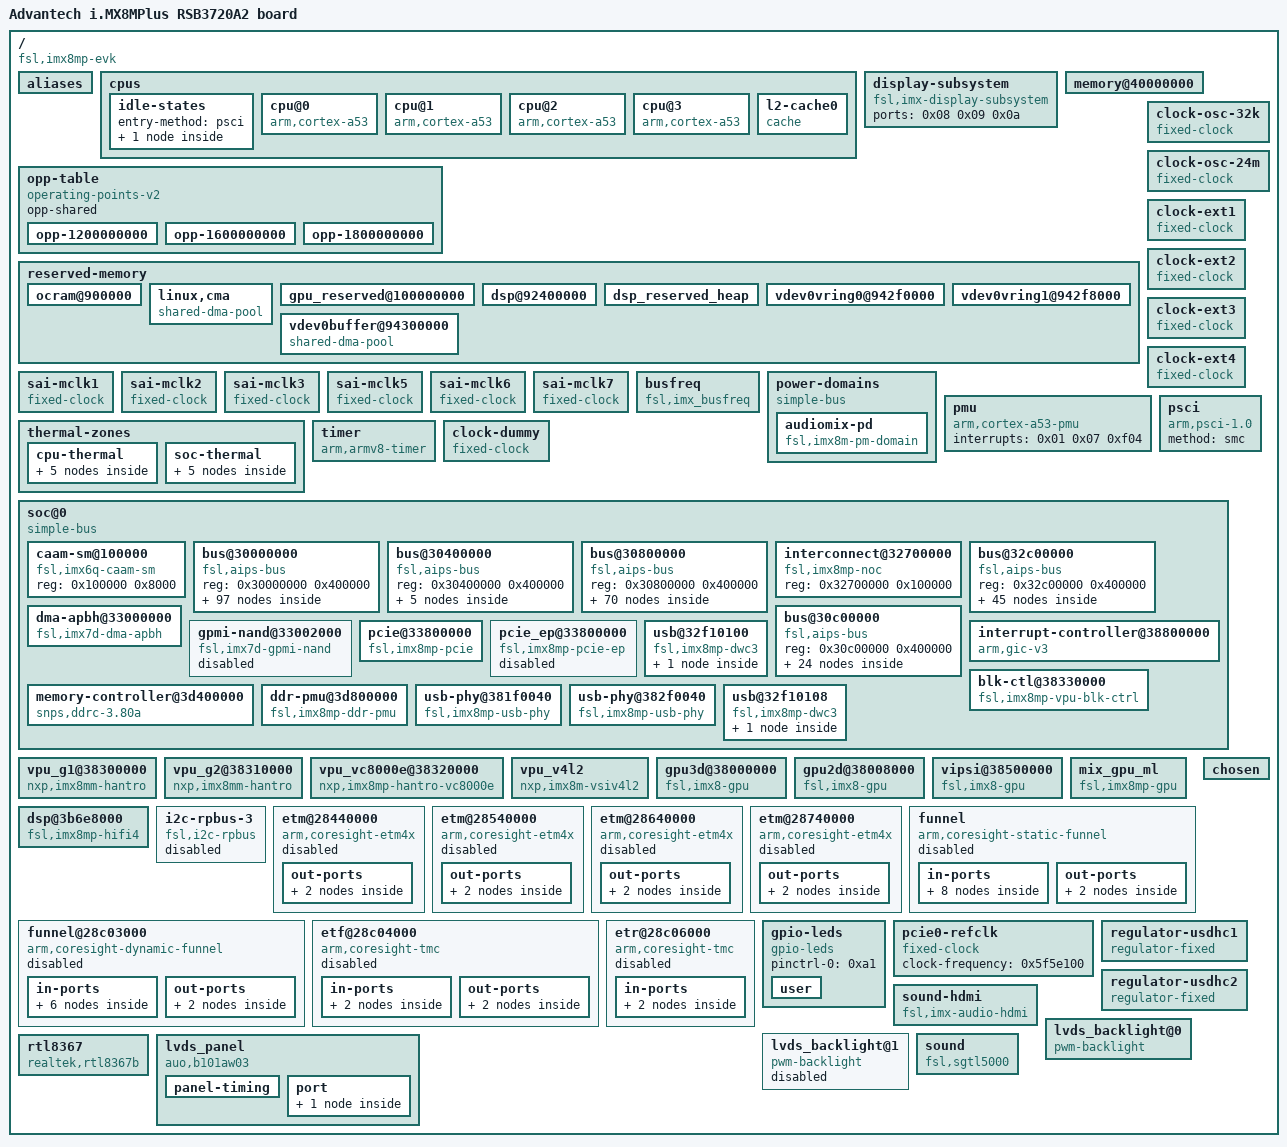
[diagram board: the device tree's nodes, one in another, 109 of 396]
/dts-v1/;

/ {
	interrupt-parent = <0x01>;
	#address-cells = <0x02>;
	#size-cells = <0x02>;
	model = "Advantech i.MX8MPlus RSB3720A2 board";
	compatible = "fsl,imx8mp-evk", "fsl,imx8mp";
	board-type = "RSB-3720 A2";

	aliases {
		ethernet0 = "/soc@0/bus@30800000/ethernet@30be0000";
		ethernet1 = "/soc@0/bus@30800000/ethernet@30bf0000";
		gpio0 = "/soc@0/bus@30000000/gpio@30200000";
		gpio1 = "/soc@0/bus@30000000/gpio@30210000";
		gpio2 = "/soc@0/bus@30000000/gpio@30220000";
		gpio3 = "/soc@0/bus@30000000/gpio@30230000";
		gpio4 = "/soc@0/bus@30000000/gpio@30240000";
		i2c0 = "/soc@0/bus@30800000/i2c@30a20000";
		i2c1 = "/soc@0/bus@30800000/i2c@30a30000";
		i2c2 = "/soc@0/bus@30800000/i2c@30a40000";
		i2c3 = "/soc@0/bus@30800000/i2c@30a50000";
		i2c4 = "/soc@0/bus@30800000/i2c@30ad0000";
		i2c5 = "/soc@0/bus@30800000/i2c@30ae0000";
		mmc0 = "/soc@0/bus@30800000/mmc@30b40000";
		mmc1 = "/soc@0/bus@30800000/mmc@30b50000";
		mmc2 = "/soc@0/bus@30800000/mmc@30b60000";
		serial0 = "/soc@0/bus@30800000/serial@30860000";
		serial1 = "/soc@0/bus@30800000/serial@30890000";
		serial2 = "/soc@0/bus@30800000/serial@30880000";
		serial3 = "/soc@0/bus@30800000/serial@30a60000";
		spi0 = "/soc@0/bus@30800000/spi@30bb0000";
		isi0 = "/soc@0/bus@32c00000/camera/isi@32e00000";
		isi1 = "/soc@0/bus@32c00000/camera/isi@32e02000";
		csi0 = "/soc@0/bus@32c00000/camera/csi@32e40000";
		csi1 = "/soc@0/bus@32c00000/camera/csi@32e50000";
		isp0 = "/soc@0/bus@32c00000/camera/isp@32e10000";
		isp1 = "/soc@0/bus@32c00000/camera/isp@32e20000";
		rtc0 = "/soc@0/bus@30800000/i2c@30a20000/s35390a@30";
		rtc1 = "/soc@0/bus@30000000/snvs@30370000/snvs-rtc-lp";
	};

	cpus {
		#address-cells = <0x01>;
		#size-cells = <0x00>;

		idle-states {
			entry-method = "psci";

			cpu-pd-wait {
				compatible = "arm,idle-state";
				arm,psci-suspend-param = <0x10033>;
				local-timer-stop;
				entry-latency-us = <0x3e8>;
				exit-latency-us = <0x2bc>;
				min-residency-us = <0xa8c>;
				wakeup-latency-us = <0x5dc>;
				phandle = <0x06>;
			};
		};

		cpu@0 {
			device_type = "cpu";
			compatible = "arm,cortex-a53";
			reg = <0x00>;
			clock-latency = <0xee6c>;
			clocks = <0x02 0x11f>;
			enable-method = "psci";
			i-cache-size = <0x8000>;
			i-cache-line-size = <0x40>;
			i-cache-sets = <0x100>;
			d-cache-size = <0x8000>;
			d-cache-line-size = <0x40>;
			d-cache-sets = <0x80>;
			next-level-cache = <0x03>;
			nvmem-cells = <0x04>;
			nvmem-cell-names = "speed_grade";
			operating-points-v2 = <0x05>;
			#cooling-cells = <0x02>;
			cpu-idle-states = <0x06>;
			cpu-supply = <0x07>;
			phandle = <0x0d>;
		};

		cpu@1 {
			device_type = "cpu";
			compatible = "arm,cortex-a53";
			reg = <0x01>;
			clock-latency = <0xee6c>;
			clocks = <0x02 0x11f>;
			enable-method = "psci";
			i-cache-size = <0x8000>;
			i-cache-line-size = <0x40>;
			i-cache-sets = <0x100>;
			d-cache-size = <0x8000>;
			d-cache-line-size = <0x40>;
			d-cache-sets = <0x80>;
			next-level-cache = <0x03>;
			operating-points-v2 = <0x05>;
			#cooling-cells = <0x02>;
			cpu-idle-states = <0x06>;
			cpu-supply = <0x07>;
			phandle = <0x0e>;
		};

		cpu@2 {
			device_type = "cpu";
			compatible = "arm,cortex-a53";
			reg = <0x02>;
			clock-latency = <0xee6c>;
			clocks = <0x02 0x11f>;
			enable-method = "psci";
			i-cache-size = <0x8000>;
			i-cache-line-size = <0x40>;
			i-cache-sets = <0x100>;
			d-cache-size = <0x8000>;
			d-cache-line-size = <0x40>;
			d-cache-sets = <0x80>;
			next-level-cache = <0x03>;
			operating-points-v2 = <0x05>;
			#cooling-cells = <0x02>;
			cpu-idle-states = <0x06>;
			cpu-supply = <0x07>;
			phandle = <0x0f>;
		};

		cpu@3 {
			device_type = "cpu";
			compatible = "arm,cortex-a53";
			reg = <0x03>;
			clock-latency = <0xee6c>;
			clocks = <0x02 0x11f>;
			enable-method = "psci";
			i-cache-size = <0x8000>;
			i-cache-line-size = <0x40>;
			i-cache-sets = <0x100>;
			d-cache-size = <0x8000>;
			d-cache-line-size = <0x40>;
			d-cache-sets = <0x80>;
			next-level-cache = <0x03>;
			operating-points-v2 = <0x05>;
			#cooling-cells = <0x02>;
			cpu-idle-states = <0x06>;
			cpu-supply = <0x07>;
			phandle = <0x10>;
		};

		l2-cache0 {
			compatible = "cache";
			cache-level = <0x02>;
			cache-size = <0x80000>;
			cache-line-size = <0x40>;
			cache-sets = <0x200>;
			phandle = <0x03>;
		};
	};

	display-subsystem {
		compatible = "fsl,imx-display-subsystem";
		ports = <0x08 0x09 0x0a>;
	};

	opp-table {
		compatible = "operating-points-v2";
		opp-shared;
		phandle = <0x05>;

		opp-1200000000 {
			opp-hz = <0x00 0x47868c00>;
			opp-microvolt = <0xcf850>;
			opp-supported-hw = <0x8a0 0x07>;
			clock-latency-ns = <0x249f0>;
			opp-suspend;
		};

		opp-1600000000 {
			opp-hz = <0x00 0x5f5e1000>;
			opp-microvolt = <0xe7ef0>;
			opp-supported-hw = <0xa0 0x07>;
			clock-latency-ns = <0x249f0>;
			opp-suspend;
		};

		opp-1800000000 {
			opp-hz = <0x00 0x6b49d200>;
			opp-microvolt = <0xf4240>;
			opp-supported-hw = <0x20 0x03>;
			clock-latency-ns = <0x249f0>;
			opp-suspend;
		};
	};

	memory@40000000 {
		device_type = "memory";
		reg = <0x00 0x40000000 0x00 0xc0000000 0x01 0x00 0x00 0xc0000000>;
	};

	reserved-memory {
		#address-cells = <0x02>;
		#size-cells = <0x02>;
		ranges;

		ocram@900000 {
			no-map;
			reg = <0x00 0x900000 0x00 0x70000>;
		};

		linux,cma {
			compatible = "shared-dma-pool";
			reusable;
			size = <0x00 0x3c000000>;
			alloc-ranges = <0x00 0x40000000 0x00 0xc0000000>;
			linux,cma-default;
		};

		gpu_reserved@100000000 {
			no-map;
			reg = <0x01 0x00 0x00 0x10000000>;
			phandle = <0x8d>;
		};

		dsp@92400000 {
			reg = <0x00 0x92400000 0x00 0x1000000>;
			no-map;
			phandle = <0x92>;
		};

		dsp_reserved_heap {
			reg = <0x00 0x93400000 0x00 0xef0000>;
			no-map;
		};

		vdev0vring0@942f0000 {
			reg = <0x00 0x942f0000 0x00 0x8000>;
			no-map;
			phandle = <0x90>;
		};

		vdev0vring1@942f8000 {
			reg = <0x00 0x942f8000 0x00 0x8000>;
			no-map;
			phandle = <0x91>;
		};

		vdev0buffer@94300000 {
			compatible = "shared-dma-pool";
			reg = <0x00 0x94300000 0x00 0x100000>;
			no-map;
			phandle = <0x8f>;
		};
	};

	clock-osc-32k {
		compatible = "fixed-clock";
		#clock-cells = <0x00>;
		clock-frequency = <0x8000>;
		clock-output-names = "osc_32k";
		phandle = <0x17>;
	};

	clock-osc-24m {
		compatible = "fixed-clock";
		#clock-cells = <0x00>;
		clock-frequency = <0x16e3600>;
		clock-output-names = "osc_24m";
		phandle = <0x18>;
	};

	clock-ext1 {
		compatible = "fixed-clock";
		#clock-cells = <0x00>;
		clock-frequency = <0x7ed6b40>;
		clock-output-names = "clk_ext1";
		phandle = <0x19>;
	};

	clock-ext2 {
		compatible = "fixed-clock";
		#clock-cells = <0x00>;
		clock-frequency = <0x7ed6b40>;
		clock-output-names = "clk_ext2";
		phandle = <0x1a>;
	};

	clock-ext3 {
		compatible = "fixed-clock";
		#clock-cells = <0x00>;
		clock-frequency = <0x7ed6b40>;
		clock-output-names = "clk_ext3";
		phandle = <0x1b>;
	};

	clock-ext4 {
		compatible = "fixed-clock";
		#clock-cells = <0x00>;
		clock-frequency = <0x7ed6b40>;
		clock-output-names = "clk_ext4";
		phandle = <0x1c>;
	};

	sai-mclk1 {
		compatible = "fixed-clock";
		#clock-cells = <0x00>;
		clock-frequency = <0x00>;
		clock-output-names = "sai1_mclk";
	};

	sai-mclk2 {
		compatible = "fixed-clock";
		#clock-cells = <0x00>;
		clock-frequency = <0x00>;
		clock-output-names = "sai2_mclk";
	};

	sai-mclk3 {
		compatible = "fixed-clock";
		#clock-cells = <0x00>;
		clock-frequency = <0x00>;
		clock-output-names = "sai3_mclk";
	};

	sai-mclk5 {
		compatible = "fixed-clock";
		#clock-cells = <0x00>;
		clock-frequency = <0x00>;
		clock-output-names = "sai5_mclk";
	};

	sai-mclk6 {
		compatible = "fixed-clock";
		#clock-cells = <0x00>;
		clock-frequency = <0x00>;
		clock-output-names = "sai6_mclk";
	};

	sai-mclk7 {
		compatible = "fixed-clock";
		#clock-cells = <0x00>;
		clock-frequency = <0x00>;
		clock-output-names = "sai7_mclk";
	};

	busfreq {
		compatible = "fsl,imx_busfreq";
		clocks = <0x02 0x29 0x02 0x70 0x02 0x71 0x02 0x71 0x02 0x11e 0x02 0x11d 0x02 0x30 0x02 0x32 0x02 0x3f 0x02 0x67 0x02 0x6b 0x02 0x5d 0x02 0x02 0x02 0x38 0x02 0x15>;
		clock-names = "dram_pll", "dram_alt_src", "dram_apb_src", "dram_apb_pre_div", "dram_core", "dram_alt_root", "sys_pll1_40m", "sys_pll1_100m", "sys_pll2_333m", "noc_div", "ahb_div", "main_axi_src", "osc_24m", "sys_pll1_800m", "dram_pll_div";
	};

	power-domains {
		compatible = "simple-bus";

		audiomix-pd {
			compatible = "fsl,imx8m-pm-domain";
			#power-domain-cells = <0x00>;
			domain-index = <0x05>;
			domain-name = "audiomix";
			clocks = <0x02 0x141 0x02 0x142>;
			phandle = <0x76>;
		};
	};

	pmu {
		compatible = "arm,cortex-a53-pmu";
		interrupts = <0x01 0x07 0xf04>;
	};

	psci {
		compatible = "arm,psci-1.0";
		method = "smc";
	};

	thermal-zones {

		cpu-thermal {
			polling-delay-passive = <0xfa>;
			polling-delay = <0x7d0>;
			thermal-sensors = <0x0b 0x00>;

			trips {

				trip0 {
					temperature = <0x14c08>;
					hysteresis = <0x7d0>;
					type = "passive";
					phandle = <0x0c>;
				};

				trip1 {
					temperature = <0x17318>;
					hysteresis = <0x7d0>;
					type = "critical";
				};
			};

			cooling-maps {

				map0 {
					trip = <0x0c>;
					cooling-device = <0x0d 0xffffffff 0xffffffff 0x0e 0xffffffff 0xffffffff 0x0f 0xffffffff 0xffffffff 0x10 0xffffffff 0xffffffff>;
				};
			};
		};

		soc-thermal {
			polling-delay-passive = <0xfa>;
			polling-delay = <0x7d0>;
			thermal-sensors = <0x0b 0x01>;

			trips {

				trip0 {
					temperature = <0x14c08>;
					hysteresis = <0x7d0>;
					type = "passive";
					phandle = <0x11>;
				};

				trip1 {
					temperature = <0x17318>;
					hysteresis = <0x7d0>;
					type = "critical";
				};
			};

			cooling-maps {

				map0 {
					trip = <0x11>;
					cooling-device = <0x0d 0xffffffff 0xffffffff 0x0e 0xffffffff 0xffffffff 0x0f 0xffffffff 0xffffffff 0x10 0xffffffff 0xffffffff>;
				};
			};
		};
	};

	timer {
		compatible = "arm,armv8-timer";
		interrupts = <0x01 0x0d 0xf08 0x01 0x0e 0xf08 0x01 0x0b 0xf08 0x01 0x0a 0xf08>;
		clock-frequency = <0x7a1200>;
		arm,no-tick-in-suspend;
		interrupt-parent = <0x01>;
	};

	clock-dummy {
		compatible = "fixed-clock";
		#clock-cells = <0x00>;
		clock-frequency = <0x00>;
		clock-output-names = "clk_dummy";
	};

	soc@0 {
		compatible = "simple-bus";
		#address-cells = <0x01>;
		#size-cells = <0x01>;
		ranges = <0x00 0x00 0x00 0x3e000000>;
		nvmem-cells = <0x12>;
		nvmem-cell-names = "soc_unique_id";

		caam-sm@100000 {
			compatible = "fsl,imx6q-caam-sm";
			reg = <0x100000 0x8000>;
		};

		bus@30000000 {
			compatible = "fsl,aips-bus", "simple-bus";
			reg = <0x30000000 0x400000>;
			#address-cells = <0x01>;
			#size-cells = <0x01>;
			ranges;

			gpio@30200000 {
				compatible = "fsl,imx8mp-gpio", "fsl,imx35-gpio";
				reg = <0x30200000 0x10000>;
				interrupts = <0x00 0x40 0x04 0x00 0x41 0x04>;
				clocks = <0x02 0xc1>;
				gpio-controller;
				#gpio-cells = <0x02>;
				interrupt-controller;
				#interrupt-cells = <0x02>;
				gpio-ranges = <0x13 0x00 0x05 0x1e>;
				phandle = <0x2c>;
			};

			gpio@30210000 {
				compatible = "fsl,imx8mp-gpio", "fsl,imx35-gpio";
				reg = <0x30210000 0x10000>;
				interrupts = <0x00 0x42 0x04 0x00 0x43 0x04>;
				clocks = <0x02 0xc2>;
				gpio-controller;
				#gpio-cells = <0x02>;
				interrupt-controller;
				#interrupt-cells = <0x02>;
				gpio-ranges = <0x13 0x00 0x23 0x15>;
				phandle = <0x38>;
			};

			gpio@30220000 {
				compatible = "fsl,imx8mp-gpio", "fsl,imx35-gpio";
				reg = <0x30220000 0x10000>;
				interrupts = <0x00 0x44 0x04 0x00 0x45 0x04>;
				clocks = <0x02 0xc3>;
				gpio-controller;
				#gpio-cells = <0x02>;
				interrupt-controller;
				#interrupt-cells = <0x02>;
				gpio-ranges = <0x13 0x00 0x38 0x1a 0x13 0x1a 0x90 0x04>;
				phandle = <0x2e>;
			};

			gpio@30230000 {
				compatible = "fsl,imx8mp-gpio", "fsl,imx35-gpio";
				reg = <0x30230000 0x10000>;
				interrupts = <0x00 0x46 0x04 0x00 0x47 0x04>;
				clocks = <0x02 0xc4>;
				gpio-controller;
				#gpio-cells = <0x02>;
				interrupt-controller;
				#interrupt-cells = <0x02>;
				gpio-ranges = <0x13 0x00 0x52 0x20>;
				phandle = <0x32>;
			};

			gpio@30240000 {
				compatible = "fsl,imx8mp-gpio", "fsl,imx35-gpio";
				reg = <0x30240000 0x10000>;
				interrupts = <0x00 0x48 0x04 0x00 0x49 0x04>;
				clocks = <0x02 0xc5>;
				gpio-controller;
				#gpio-cells = <0x02>;
				interrupt-controller;
				#interrupt-cells = <0x02>;
				gpio-ranges = <0x13 0x00 0x72 0x1e>;
				phandle = <0x2a>;
			};

			tmu@30260000 {
				compatible = "fsl,imx8mp-tmu";
				reg = <0x30260000 0x10000>;
				clocks = <0x02 0x119>;
				#thermal-sensor-cells = <0x01>;
				phandle = <0x0b>;
			};

			watchdog@30280000 {
				compatible = "fsl,imx8mp-wdt", "fsl,imx21-wdt";
				reg = <0x30280000 0x10000>;
				interrupts = <0x00 0x4e 0x04>;
				clocks = <0x02 0x103>;
				status = "disabled";
				pinctrl-names = "default";
				pinctrl-0 = <0x14>;
				fsl,ext-reset-output;
			};

			watchdog@30290000 {
				compatible = "fsl,imx8mp-wdt", "fsl,imx21-wdt";
				reg = <0x30290000 0x10000>;
				interrupts = <0x00 0x4f 0x04>;
				clocks = <0x02 0x104>;
				status = "disabled";
			};

			watchdog@302a0000 {
				compatible = "fsl,imx8mp-wdt", "fsl,imx21-wdt";
				reg = <0x302a0000 0x10000>;
				interrupts = <0x00 0x0a 0x04>;
				clocks = <0x02 0x105>;
				status = "disabled";
			};

			pinctrl@30330000 {
				compatible = "fsl,imx8mp-iomuxc";
				reg = <0x30330000 0x10000>;
				pinctrl-names = "default";
				pinctrl-0 = <0x15>;
				phandle = <0x13>;

				hoggrp {
					fsl,pins = <0x240 0x4a0 0x00 0x00 0x00 0x400001c2 0x244 0x4a4 0x00 0x00 0x00 0x400001c2 0x24c 0x4ac 0x00 0x00 0x00 0x40000010 0x248 0x4a8 0x00 0x00 0x00 0x40000010 0x148 0x3a8 0x00 0x05 0x00 0x1c4 0x14c 0x3ac 0x00 0x05 0x00 0x1c4 0x1dc 0x43c 0x00 0x05 0x00 0x1c4 0x1f4 0x454 0x00 0x05 0x00 0x10 0x1f0 0x450 0x00 0x05 0x00 0x10>;
					phandle = <0x15>;
				};

				pwm2grp {
					fsl,pins = <0x134 0x394 0x00 0x02 0x00 0x116>;
					phandle = <0x1f>;
				};

				pwm3grp {
					fsl,pins = <0x130 0x390 0x00 0x02 0x00 0x116>;
					phandle = <0x20>;
				};

				eqosgrp {
					fsl,pins = <0x54 0x2b4 0x00 0x00 0x00 0x02 0x58 0x2b8 0x590 0x00 0x01 0x02 0x7c 0x2dc 0x00 0x00 0x00 0x90 0x80 0x2e0 0x00 0x00 0x00 0x90 0x84 0x2e4 0x00 0x00 0x00 0x90 0x88 0x2e8 0x00 0x00 0x00 0x90 0x78 0x2d8 0x00 0x00 0x00 0x90 0x74 0x2d4 0x00 0x00 0x00 0x90 0x68 0x2c8 0x00 0x00 0x00 0x16 0x64 0x2c4 0x00 0x00 0x00 0x16 0x60 0x2c0 0x00 0x00 0x00 0x16 0x5c 0x2bc 0x00 0x00 0x00 0x16 0x6c 0x2cc 0x00 0x00 0x00 0x16 0x70 0x2d0 0x00 0x00 0x00 0x16 0x1a0 0x400 0x00 0x05 0x00 0x10 0x19c 0x3fc 0x00 0x05 0x00 0x1c4>;
					phandle = <0x55>;
				};

				fecgrp {
					fsl,pins = <0x158 0x3b8 0x00 0x04 0x00 0x02 0x15c 0x3bc 0x57c 0x04 0x01 0x02 0x160 0x3c0 0x580 0x04 0x01 0x90 0x164 0x3c4 0x584 0x04 0x01 0x90 0x168 0x3c8 0x00 0x04 0x00 0x90 0x16c 0x3cc 0x00 0x04 0x00 0x90 0x174 0x3d4 0x00 0x04 0x00 0x90 0x170 0x3d0 0x588 0x04 0x01 0x90 0x178 0x3d8 0x00 0x04 0x00 0x16 0x17c 0x3dc 0x00 0x04 0x00 0x16 0x180 0x3e0 0x00 0x04 0x00 0x16 0x184 0x3e4 0x00 0x04 0x00 0x16 0x188 0x3e8 0x00 0x04 0x00 0x16 0x18c 0x3ec 0x00 0x04 0x00 0x16 0x150 0x3b0 0x00 0x05 0x00 0x10 0x154 0x3b4 0x00 0x05 0x00 0x1c4>;
					phandle = <0x52>;
				};

				flexcan1grp {
					fsl,pins = <0x1d8 0x438 0x54c 0x04 0x02 0x154 0x1d4 0x434 0x00 0x04 0x00 0x154>;
					phandle = <0x26>;
				};

				flexcan2grp {
					fsl,pins = <0x144 0x3a4 0x550 0x06 0x00 0x154 0x140 0x3a0 0x00 0x06 0x00 0x154>;
					phandle = <0x27>;
				};

				flexspi0grp {
					fsl,pins = <0xe0 0x340 0x00 0x01 0x00 0x1c2 0xe4 0x344 0x00 0x01 0x00 0x82 0xf8 0x358 0x00 0x01 0x00 0x82 0xfc 0x35c 0x00 0x01 0x00 0x82 0x100 0x360 0x00 0x01 0x00 0x82 0x104 0x364 0x00 0x01 0x00 0x82>;
					phandle = <0x50>;
				};

				gpioledgrp {
					fsl,pins = <0x1b4 0x414 0x00 0x05 0x00 0x10>;
					phandle = <0xa1>;
				};

				i2c1grp {
					fsl,pins = <0x200 0x460 0x5a4 0x00 0x02 0x400001c2 0x204 0x464 0x5a8 0x00 0x02 0x400001c2>;
					phandle = <0x28>;
				};

				i2c1_gpio_grp {
					fsl,pins = <0x200 0x460 0x00 0x05 0x00 0x10 0x204 0x464 0x00 0x05 0x00 0x10>;
					phandle = <0x29>;
				};

				i2c2grp {
					fsl,pins = <0x208 0x468 0x5ac 0x00 0x02 0x400001c2 0x20c 0x46c 0x5b0 0x00 0x02 0x400001c2>;
					phandle = <0x33>;
				};

				i2c2_gpio_grp {
					fsl,pins = <0x208 0x468 0x00 0x05 0x00 0x10 0x20c 0x46c 0x00 0x05 0x00 0x10>;
					phandle = <0x34>;
				};

				i2c3grp {
					fsl,pins = <0x210 0x470 0x5b4 0x00 0x04 0x400001c2 0x214 0x474 0x5b8 0x00 0x04 0x400001c2>;
					phandle = <0x3a>;
				};

				i2c3_gpio_grp {
					fsl,pins = <0x210 0x470 0x00 0x05 0x00 0x10 0x214 0x474 0x00 0x05 0x00 0x10>;
					phandle = <0x3b>;
				};

				i2c4grp {
					fsl,pins = <0x1f8 0x458 0x5bc 0x02 0x04 0x400001c2 0x1fc 0x45c 0x5c0 0x02 0x04 0x400001c2>;
					phandle = <0x40>;
				};

				i2c4_gpio_grp {
					fsl,pins = <0x1f8 0x458 0x00 0x05 0x00 0x10 0x1fc 0x45c 0x00 0x05 0x00 0x10>;
					phandle = <0x41>;
				};

				pcie0grp {
					fsl,pins = <0x218 0x478 0x5a0 0x12 0x00 0x60 0x21c 0x47c 0x00 0x05 0x00 0x1c4 0x38 0x298 0x00 0x00 0x00 0x40 0x3c 0x29c 0x00 0x00 0x00 0x40 0x40 0x2a0 0x00 0x00 0x00 0x40 0x44 0x2a4 0x00 0x00 0x00 0x40 0x28 0x288 0x00 0x00 0x00 0x40 0x2c 0x28c 0x00 0x00 0x00 0x40 0x30 0x290 0x00 0x00 0x00 0x40 0x34 0x294 0x00 0x00 0x00 0x40>;
					phandle = <0x80>;
				};

				pmicgrp {
					fsl,pins = <0x20 0x280 0x00 0x00 0x00 0x1c0>;
					phandle = <0x2b>;
				};

				regusdhc1vmmcgrp {
					fsl,pins = <0xb4 0x314 0x00 0x05 0x00 0x40>;
					phandle = <0xa2>;
				};

				regusdhc2vmmcgrp {
					fsl,pins = <0xd8 0x338 0x00 0x05 0x00 0x40>;
					phandle = <0xa3>;
				};

				sai2grp {
					fsl,pins = <0x1ac 0x40c 0x00 0x00 0x00 0xd6 0x1a8 0x408 0x00 0x00 0x00 0xd6 0x1b0 0x410 0x00 0x00 0x00 0xd6 0x1a4 0x404 0x00 0x00 0x00 0xd6>;
					phandle = <0x77>;
				};

				sai3grp {
					fsl,pins = <0x1c4 0x424 0x4ec 0x00 0x01 0xd6 0x1c8 0x428 0x4e8 0x00 0x01 0xd6 0x1c0 0x420 0x4e4 0x00 0x01 0xd6 0x1cc 0x42c 0x00 0x00 0x00 0xd6 0x1d0 0x430 0x4e0 0x00 0x02 0xd6>;
					phandle = <0x78>;
				};

				uart1grp {
					fsl,pins = <0x220 0x480 0x5e8 0x00 0x04 0x140 0x224 0x484 0x00 0x00 0x00 0x140 0x230 0x490 0x00 0x01 0x00 0x140 0x234 0x494 0x5e4 0x01 0x05 0x140>;
					phandle = <0x22>;
				};

				uart2grp {
					fsl,pins = <0x228 0x488 0x5f0 0x00 0x06 0x140 0x22c 0x48c 0x00 0x00 0x00 0x140>;
					phandle = <0x24>;
				};

				uart3grp {
					fsl,pins = <0x1e0 0x440 0x5f8 0x01 0x04 0x140 0x1e4 0x444 0x00 0x01 0x00 0x140 0x1ec 0x44c 0x5f4 0x01 0x03 0x140 0x1e8 0x448 0x00 0x01 0x00 0x140>;
					phandle = <0x23>;
				};

				uart4grp {
					fsl,pins = <0x238 0x498 0x600 0x00 0x08 0x140 0x23c 0x49c 0x00 0x00 0x00 0x140>;
					phandle = <0x42>;
				};

				usdhc1grp {
					fsl,pins = <0x8c 0x2ec 0x00 0x00 0x00 0x190 0x90 0x2f0 0x00 0x00 0x00 0x1d0 0x94 0x2f4 0x00 0x00 0x00 0x1d0 0x98 0x2f8 0x00 0x00 0x00 0x1d0 0x9c 0x2fc 0x00 0x00 0x00 0x1d0 0xa0 0x300 0x00 0x00 0x00 0x1d0>;
					phandle = <0x43>;
				};

				usdhc1-100mhzgrp {
					fsl,pins = <0x8c 0x2ec 0x00 0x00 0x00 0x194 0x90 0x2f0 0x00 0x00 0x00 0x1d4 0x94 0x2f4 0x00 0x00 0x00 0x1d4 0x98 0x2f8 0x00 0x00 0x00 0x1d4 0x9c 0x2fc 0x00 0x00 0x00 0x1d4 0xa0 0x300 0x00 0x00 0x00 0x1d4>;
					phandle = <0x45>;
				};

				usdhc1-200mhzgrp {
					fsl,pins = <0x8c 0x2ec 0x00 0x00 0x00 0x196 0x90 0x2f0 0x00 0x00 0x00 0x1d6 0x94 0x2f4 0x00 0x00 0x00 0x1d6 0x98 0x2f8 0x00 0x00 0x00 0x1d6 0x9c 0x2fc 0x00 0x00 0x00 0x1d6 0xa0 0x300 0x00 0x00 0x00 0x1d6>;
					phandle = <0x46>;
				};

				usdhc1gpiogrp {
					fsl,pins = <0xb8 0x318 0x00 0x05 0x00 0x10>;
					phandle = <0x44>;
				};

				usdhc2grp {
					fsl,pins = <0xc0 0x320 0x00 0x00 0x00 0x190 0xc4 0x324 0x00 0x00 0x00 0x1d0 0xc8 0x328 0x00 0x00 0x00 0x1d0 0xcc 0x32c 0x00 0x00 0x00 0x1d0 0xd0 0x330 0x00 0x00 0x00 0x1d0 0xd4 0x334 0x00 0x00 0x00 0x1d0 0x24 0x284 0x00 0x01 0x00 0xc0>;
					phandle = <0x48>;
				};

				usdhc2-100mhzgrp {
					fsl,pins = <0xc0 0x320 0x00 0x00 0x00 0x194 0xc4 0x324 0x00 0x00 0x00 0x1d4 0xc8 0x328 0x00 0x00 0x00 0x1d4 0xcc 0x32c 0x00 0x00 0x00 0x1d4 0xd0 0x330 0x00 0x00 0x00 0x1d4 0xd4 0x334 0x00 0x00 0x00 0x1d4 0x24 0x284 0x00 0x01 0x00 0xc0>;
					phandle = <0x4a>;
				};

				usdhc2-200mhzgrp {
					fsl,pins = <0xc0 0x320 0x00 0x00 0x00 0x196 0xc4 0x324 0x00 0x00 0x00 0x1d6 0xc8 0x328 0x00 0x00 0x00 0x1d6 0xcc 0x32c 0x00 0x00 0x00 0x1d6 0xd0 0x330 0x00 0x00 0x00 0x1d6 0xd4 0x334 0x00 0x00 0x00 0x1d6 0x24 0x284 0x00 0x01 0x00 0xc0>;
					phandle = <0x4b>;
				};

				usdhc2gpiogrp {
					fsl,pins = <0xbc 0x31c 0x00 0x05 0x00 0x1c4>;
					phandle = <0x49>;
				};

				usdhc3grp {
					fsl,pins = <0x124 0x384 0x604 0x02 0x01 0x190 0x128 0x388 0x60c 0x02 0x01 0x1d0 0x108 0x368 0x610 0x02 0x01 0x1d0 0x10c 0x36c 0x614 0x02 0x01 0x1d0 0x110 0x370 0x618 0x02 0x01 0x1d0 0x114 0x374 0x61c 0x02 0x01 0x1d0 0x11c 0x37c 0x620 0x02 0x01 0x1d0 0xec 0x34c 0x624 0x02 0x01 0x1d0 0xf0 0x350 0x628 0x02 0x01 0x1d0 0xf4 0x354 0x62c 0x02 0x01 0x1d0 0xe8 0x348 0x630 0x02 0x01 0x190>;
					phandle = <0x4d>;
				};

				usdhc3-100mhzgrp {
					fsl,pins = <0x124 0x384 0x604 0x02 0x01 0x194 0x128 0x388 0x60c 0x02 0x01 0x1d4 0x108 0x368 0x610 0x02 0x01 0x1d4 0x10c 0x36c 0x614 0x02 0x01 0x1d4 0x110 0x370 0x618 0x02 0x01 0x1d4 0x114 0x374 0x61c 0x02 0x01 0x1d4 0x11c 0x37c 0x620 0x02 0x01 0x1d4 0xec 0x34c 0x624 0x02 0x01 0x1d4 0xf0 0x350 0x628 0x02 0x01 0x1d4 0xf4 0x354 0x62c 0x02 0x01 0x1d4 0xe8 0x348 0x630 0x02 0x01 0x194>;
					phandle = <0x4e>;
				};

				usdhc3-200mhzgrp {
					fsl,pins = <0x124 0x384 0x604 0x02 0x01 0x196 0x128 0x388 0x60c 0x02 0x01 0x1d6 0x108 0x368 0x610 0x02 0x01 0x1d6 0x10c 0x36c 0x614 0x02 0x01 0x1d6 0x110 0x370 0x618 0x02 0x01 0x1d6 0x114 0x374 0x61c 0x02 0x01 0x1d6 0x11c 0x37c 0x620 0x02 0x01 0x1d6 0xec 0x34c 0x624 0x02 0x01 0x1d6 0xf0 0x350 0x628 0x02 0x01 0x1d6 0xf4 0x354 0x62c 0x02 0x01 0x1d6 0xe8 0x348 0x630 0x02 0x01 0x196>;
					phandle = <0x4f>;
				};

				wdoggrp {
					fsl,pins = <0x1c 0x27c 0x00 0x01 0x00 0x166>;
					phandle = <0x14>;
				};

				csi0_pwn_grp {
					fsl,pins = <0xa4 0x304 0x00 0x05 0x00 0x10>;
					phandle = <0x35>;
				};

				csi0_rst_grp {
					fsl,pins = <0xa8 0x308 0x00 0x05 0x00 0x10>;
					phandle = <0x36>;
				};

				csi0_mclk_grp {
					fsl,pins = <0x4c 0x2ac 0x00 0x06 0x00 0x50>;
					phandle = <0x37>;
				};

				csi1_pwn_grp {
					fsl,pins = <0xac 0x30c 0x00 0x05 0x00 0x10>;
					phandle = <0x3c>;
				};

				csi1_rst_grp {
					fsl,pins = <0xb0 0x310 0x00 0x05 0x00 0x10>;
					phandle = <0x3d>;
				};

				csi1_mclk_grp {
					fsl,pins = <0x50 0x2b0 0x00 0x06 0x00 0x50>;
					phandle = <0x3e>;
				};

				lvds_vcc_grp {
					fsl,pins = <0x48 0x2a8 0x00 0x00 0x00 0x10>;
					phandle = <0xa6>;
				};

				bklt_vcc_0_grp {
					fsl,pins = <0x14 0x274 0x00 0x00 0x00 0x10>;
					phandle = <0xa7>;
				};

				bklt_vcc_1_grp {
					fsl,pins = <0x18 0x278 0x00 0x00 0x00 0x10>;
				};

				wdt_engrp-1 {
					fsl,pins = <0x12c 0x38c 0x00 0x05 0x00 0x10>;
					phandle = <0x30>;
				};

				wdt_pinggrp-1 {
					fsl,pins = <0x198 0x3f8 0x00 0x05 0x00 0x10>;
					phandle = <0x31>;
				};

				tpm_grp {
					fsl,pins = <0x138 0x398 0x00 0x05 0x00 0x10 0x13c 0x39c 0x00 0x05 0x00 0x1c4>;
					phandle = <0x2d>;
				};
			};

			iomuxc-gpr@30340000 {
				compatible = "fsl,imx8mp-iomuxc-gpr", "syscon";
				reg = <0x30340000 0x10000>;
				phandle = <0x25>;
			};

			efuse@30350000 {
				compatible = "fsl,imx8mp-ocotp", "fsl,imx8mm-ocotp", "syscon", "simple-mfd";
				reg = <0x30350000 0x10000>;
				clocks = <0x02 0xd6>;
				#address-cells = <0x01>;
				#size-cells = <0x01>;

				unique-id@8 {
					reg = <0x08 0x08>;
					phandle = <0x12>;
				};

				speed-grade@10 {
					reg = <0x10 0x04>;
					phandle = <0x04>;
				};

				mac-address@90 {
					reg = <0x90 0x06>;
					phandle = <0x51>;
				};

				mac-address@96 {
					reg = <0x96 0x06>;
					phandle = <0x54>;
				};

				imx8mp-soc {
					compatible = "fsl,imx8mp-soc";
					nvmem-cells = <0x12>;
					nvmem-cell-names = "soc_unique_id";
				};
			};

			anatop@30360000 {
				compatible = "fsl,imx8mp-anatop", "fsl,imx8mm-anatop", "syscon";
				reg = <0x30360000 0x10000>;
			};

			caam_secvio {
				compatible = "fsl,imx6q-caam-secvio";
				interrupts = <0x00 0x14 0x04>;
				jtag-tamper = "disabled";
				watchdog-tamper = "enabled";
				internal-boot-tamper = "enabled";
				external-pin-tamper = "disabled";
			};

			caam-snvs@30370000 {
				compatible = "fsl,imx6q-caam-snvs";
				reg = <0x30370000 0x10000>;
				clocks = <0x02 0xf9>;
				clock-names = "ipg";
			};

			snvs@30370000 {
				compatible = "fsl,sec-v4.0-mon", "syscon", "simple-mfd";
				reg = <0x30370000 0x10000>;
				phandle = <0x16>;

				snvs-rtc-lp {
					compatible = "fsl,sec-v4.0-mon-rtc-lp";
					regmap = <0x16>;
					offset = <0x34>;
					interrupts = <0x00 0x13 0x04 0x00 0x14 0x04>;
					clocks = <0x02 0xf9>;
					clock-names = "snvs-rtc";
				};

				snvs-powerkey {
					compatible = "fsl,sec-v4.0-pwrkey";
					regmap = <0x16>;
					interrupts = <0x00 0x04 0x04>;
					clocks = <0x02 0xf9>;
					clock-names = "snvs-pwrkey";
					linux,keycode = <0x74>;
					wakeup-source;
					status = "okay";
				};

				snvs-lpgpr {
					compatible = "fsl,imx8mp-snvs-lpgpr", "fsl,imx7d-snvs-lpgpr";
				};
			};

			clock-controller@30380000 {
				compatible = "fsl,imx8mp-ccm";
				reg = <0x30380000 0x10000>;
				#clock-cells = <0x01>;
				clocks = <0x17 0x18 0x19 0x1a 0x1b 0x1c>;
				clock-names = "osc_32k", "osc_24m", "clk_ext1", "clk_ext2", "clk_ext3", "clk_ext4";
				assigned-clocks = <0x02 0x42 0x02 0x120 0x02 0x67 0x02 0x68 0x02 0x94 0x02 0x6c 0x02 0x48 0x02 0x12 0x02 0x13 0x02 0x14>;
				assigned-clock-parents = <0x02 0x38 0x02 0x2c 0x02 0x41 0x02 0x38 0x02 0x40 0x02 0x38 0x02 0x38>;
				assigned-clock-rates = <0x00 0x00 0x3b9aca00 0x2faf0800 0x1dcd6500 0x17d78400 0x2faf0800 0x17700000 0x15888000 0x3df582e0>;
				phandle = <0x02>;
			};

			reset-controller@30390000 {
				compatible = "fsl,imx8mp-src", "syscon";
				reg = <0x30390000 0x10000>;
				interrupts = <0x00 0x59 0x04>;
				#reset-cells = <0x01>;
				phandle = <0x62>;
			};

			gpc@303a0000 {
				compatible = "fsl,imx8mp-gpc";
				reg = <0x303a0000 0x1000>;
				interrupt-parent = <0x01>;
				interrupts = <0x00 0x57 0x04>;
				interrupt-controller;
				#interrupt-cells = <0x03>;

				pgc {
					#address-cells = <0x01>;
					#size-cells = <0x00>;

					power-domain@0 {
						#power-domain-cells = <0x00>;
						reg = <0x00>;
						phandle = <0x5f>;
					};

					power-domain@1 {
						#power-domain-cells = <0x00>;
						reg = <0x01>;
						phandle = <0x68>;
					};

					power-domain@2 {
						#power-domain-cells = <0x00>;
						reg = <0x02>;
						phandle = <0x66>;
					};

					power-domain@3 {
						#power-domain-cells = <0x00>;
						reg = <0x03>;
						phandle = <0x67>;
					};

					power-domain@7 {
						#power-domain-cells = <0x00>;
						reg = <0x07>;
						clocks = <0x02 0x107 0x02 0x65 0x02 0x66>;
						assigned-clocks = <0x02 0x65 0x02 0x66>;
						assigned-clock-parents = <0x02 0x38 0x02 0x38>;
						assigned-clock-rates = <0x2faf0800 0x17d78400>;
						phandle = <0x1d>;
					};

					power-domain@6 {
						#power-domain-cells = <0x00>;
						reg = <0x06>;
						clocks = <0x02 0xf7>;
						power-domains = <0x1d>;
						phandle = <0x88>;
					};

					power-domain@9 {
						#power-domain-cells = <0x00>;
						reg = <0x09>;
						clocks = <0x02 0xf8 0x02 0x134>;
						power-domains = <0x1d>;
						phandle = <0x87>;
					};

					power-domain@10 {
						#power-domain-cells = <0x00>;
						reg = <0x0a>;
						clocks = <0x02 0x10e 0x02 0x10d>;
						phandle = <0x5e>;
					};

					power-domains@14 {
						#power-domain-cells = <0x00>;
						reg = <0x0e>;
						clocks = <0x02 0x116 0x02 0x63>;
						assigned-clocks = <0x02 0x64 0x02 0x63>;
						assigned-clock-parents = <0x02 0x40 0x02 0x33>;
						assigned-clock-rates = <0x1dcd6500 0x7ed6b40>;
						phandle = <0x69>;
					};

					power-domains@15 {
						#power-domain-cells = <0x00>;
						reg = <0x0f>;
						phandle = <0x6a>;
					};

					power-domain@16 {
						#power-domain-cells = <0x00>;
						reg = <0x10>;
						phandle = <0x60>;
					};

					power-domain@17 {
						#power-domain-cells = <0x00>;
						reg = <0x11>;
						clocks = <0x02 0x137 0x02 0x10c>;
						assigned-clocks = <0x02 0x137>;
						assigned-clock-parents = <0x02 0x40>;
						assigned-clock-rates = <0x1dcd6500>;
						phandle = <0x65>;
					};

					power-domain@18 {
						#power-domain-cells = <0x00>;
						reg = <0x12>;
						clocks = <0x02 0x114>;
						phandle = <0x61>;
					};

					power-domain@19 {
						#power-domain-cells = <0x00>;
						reg = <0x08>;
						clocks = <0x02 0x11a>;
						phandle = <0x1e>;
					};

					power-domain@20 {
						#power-domain-cells = <0x00>;
						power-domains = <0x1e>;
						reg = <0x0b>;
						clocks = <0x02 0x106>;
						phandle = <0x81>;
					};

					power-domain@21 {
						#power-domain-cells = <0x00>;
						power-domains = <0x1e>;
						reg = <0x0c>;
						clocks = <0x02 0x10a>;
						phandle = <0x82>;
					};

					power-domain@22 {
						#power-domain-cells = <0x00>;
						power-domains = <0x1e>;
						reg = <0x0d>;
						clocks = <0x02 0x109>;
						phandle = <0x83>;
					};

					power-domain@24 {
						#power-domain-cells = <0x00>;
						reg = <0x04>;
						clocks = <0x02 0x69 0x02 0x6a 0x02 0x10b>;
						phandle = <0x89>;
					};
				};
			};
		};

		bus@30400000 {
			compatible = "fsl,aips-bus", "simple-bus";
			reg = <0x30400000 0x400000>;
			#address-cells = <0x01>;
			#size-cells = <0x01>;
			ranges;

			pwm@30660000 {
				compatible = "fsl,imx8mp-pwm", "fsl,imx27-pwm";
				reg = <0x30660000 0x10000>;
				interrupts = <0x00 0x51 0x04>;
				clocks = <0x02 0xdc 0x02 0xdc>;
				clock-names = "ipg", "per";
				#pwm-cells = <0x03>;
				status = "disabled";
			};

			pwm@30670000 {
				compatible = "fsl,imx8mp-pwm", "fsl,imx27-pwm";
				reg = <0x30670000 0x10000>;
				interrupts = <0x00 0x52 0x04>;
				clocks = <0x02 0xdd 0x02 0xdd>;
				clock-names = "ipg", "per";
				#pwm-cells = <0x03>;
				status = "okay";
				pinctrl-names = "default";
				pinctrl-0 = <0x1f>;
				phandle = <0xa5>;
			};

			pwm@30680000 {
				compatible = "fsl,imx8mp-pwm", "fsl,imx27-pwm";
				reg = <0x30680000 0x10000>;
				interrupts = <0x00 0x53 0x04>;
				clocks = <0x02 0xde 0x02 0xde>;
				clock-names = "ipg", "per";
				#pwm-cells = <0x03>;
				status = "okay";
				pinctrl-names = "default";
				pinctrl-0 = <0x20>;
				phandle = <0xa9>;
			};

			pwm@30690000 {
				compatible = "fsl,imx8mp-pwm", "fsl,imx27-pwm";
				reg = <0x30690000 0x10000>;
				interrupts = <0x00 0x54 0x04>;
				clocks = <0x02 0xdf 0x02 0xdf>;
				clock-names = "ipg", "per";
				#pwm-cells = <0x03>;
				status = "disabled";
			};

			timer@306a0000 {
				compatible = "nxp,sysctr-timer";
				reg = <0x306a0000 0x20000>;
				interrupts = <0x00 0x2f 0x04>;
				clocks = <0x18>;
				clock-names = "per";
			};
		};

		bus@30800000 {
			compatible = "fsl,aips-bus", "simple-bus";
			reg = <0x30800000 0x400000>;
			#address-cells = <0x01>;
			#size-cells = <0x01>;
			ranges;

			spi@30820000 {
				#address-cells = <0x01>;
				#size-cells = <0x00>;
				compatible = "fsl,imx8mp-ecspi", "fsl,imx6ul-ecspi";
				reg = <0x30820000 0x10000>;
				interrupts = <0x00 0x1f 0x04>;
				clocks = <0x02 0xbd 0x02 0xbd>;
				clock-names = "ipg", "per";
				assigned-clock-rates = <0x4c4b400>;
				assigned-clocks = <0x02 0x95>;
				assigned-clock-parents = <0x02 0x38>;
				dmas = <0x21 0x00 0x07 0x01 0x21 0x01 0x07 0x02>;
				dma-names = "rx", "tx";
				status = "disabled";
			};

			spi@30830000 {
				#address-cells = <0x01>;
				#size-cells = <0x00>;
				compatible = "fsl,imx8mp-ecspi", "fsl,imx6ul-ecspi";
				reg = <0x30830000 0x10000>;
				interrupts = <0x00 0x20 0x04>;
				clocks = <0x02 0xbe 0x02 0xbe>;
				clock-names = "ipg", "per";
				assigned-clock-rates = <0x4c4b400>;
				assigned-clocks = <0x02 0x96>;
				assigned-clock-parents = <0x02 0x38>;
				dmas = <0x21 0x02 0x07 0x01 0x21 0x03 0x07 0x02>;
				dma-names = "rx", "tx";
				status = "disabled";
			};

			spi@30840000 {
				#address-cells = <0x01>;
				#size-cells = <0x00>;
				compatible = "fsl,imx8mp-ecspi", "fsl,imx6ul-ecspi";
				reg = <0x30840000 0x10000>;
				interrupts = <0x00 0x21 0x04>;
				clocks = <0x02 0xbf 0x02 0xbf>;
				clock-names = "ipg", "per";
				assigned-clock-rates = <0x4c4b400>;
				assigned-clocks = <0x02 0xb3>;
				assigned-clock-parents = <0x02 0x38>;
				dmas = <0x21 0x04 0x07 0x01 0x21 0x05 0x07 0x02>;
				dma-names = "rx", "tx";
				status = "disabled";
			};

			serial@30860000 {
				compatible = "fsl,imx8mp-uart", "fsl,imx6q-uart";
				reg = <0x30860000 0x10000>;
				interrupts = <0x00 0x1a 0x04>;
				clocks = <0x02 0xfb 0x02 0xfb>;
				clock-names = "ipg", "per";
				dmas = <0x21 0x16 0x04 0x00 0x21 0x17 0x04 0x00>;
				dma-names = "rx", "tx";
				status = "okay";
				pinctrl-names = "default";
				pinctrl-0 = <0x22>;
				assigned-clocks = <0x02 0x8e>;
				assigned-clock-parents = <0x02 0x31>;
				fsl,uart-has-rtscts;
			};

			serial@30880000 {
				compatible = "fsl,imx8mp-uart", "fsl,imx6q-uart";
				reg = <0x30880000 0x10000>;
				interrupts = <0x00 0x1c 0x04>;
				clocks = <0x02 0xfd 0x02 0xfd>;
				clock-names = "ipg", "per";
				dmas = <0x21 0x1a 0x04 0x00 0x21 0x1b 0x04 0x00>;
				dma-names = "rx", "tx";
				status = "okay";
				pinctrl-names = "default";
				pinctrl-0 = <0x23>;
				assigned-clocks = <0x02 0x90>;
				assigned-clock-parents = <0x02 0x31>;
				fsl,uart-has-rtscts;
				linux,rs485-enabled-at-boot-time;
				rs485-rx-during-tx;
				rs485-rts-active-low;
			};

			serial@30890000 {
				compatible = "fsl,imx8mp-uart", "fsl,imx6q-uart";
				reg = <0x30890000 0x10000>;
				interrupts = <0x00 0x1b 0x04>;
				clocks = <0x02 0xfc 0x02 0xfc>;
				clock-names = "ipg", "per";
				dmas = <0x21 0x18 0x04 0x00 0x21 0x19 0x04 0x00>;
				dma-names = "rx", "tx";
				status = "okay";
				pinctrl-names = "default";
				pinctrl-0 = <0x24>;
			};

			can@308c0000 {
				compatible = "fsl,imx8mp-flexcan";
				reg = <0x308c0000 0x10000>;
				interrupts = <0x00 0x8e 0x04>;
				clocks = <0x02 0x6e 0x02 0xe9>;
				clock-names = "ipg", "per";
				assigned-clocks = <0x02 0x74>;
				assigned-clock-parents = <0x02 0x30>;
				assigned-clock-rates = <0x2625a00>;
				fsl,clk-source = [00];
				fsl,stop-mode = <0x25 0x10 0x04>;
				status = "okay";
				pinctrl-names = "default";
				pinctrl-0 = <0x26>;
			};

			can@308d0000 {
				compatible = "fsl,imx8mp-flexcan";
				reg = <0x308d0000 0x10000>;
				interrupts = <0x00 0x90 0x04>;
				clocks = <0x02 0x6e 0x02 0xea>;
				clock-names = "ipg", "per";
				assigned-clocks = <0x02 0x75>;
				assigned-clock-parents = <0x02 0x30>;
				assigned-clock-rates = <0x2625a00>;
				fsl,clk-source = [00];
				fsl,stop-mode = <0x25 0x10 0x05>;
				status = "okay";
				pinctrl-names = "default";
				pinctrl-0 = <0x27>;
			};

			crypto@30900000 {
				compatible = "fsl,sec-v4.0";
				#address-cells = <0x01>;
				#size-cells = <0x01>;
				reg = <0x30900000 0x40000>;
				ranges = <0x00 0x30900000 0x40000>;
				interrupts = <0x00 0x5b 0x04>;
				clocks = <0x02 0x6b 0x02 0x6e>;
				clock-names = "aclk", "ipg";

				jr@1000 {
					compatible = "fsl,sec-v4.0-job-ring";
					reg = <0x1000 0x1000>;
					interrupts = <0x00 0x69 0x04>;
					status = "disabled";
				};

				jr@2000 {
					compatible = "fsl,sec-v4.0-job-ring";
					reg = <0x2000 0x1000>;
					interrupts = <0x00 0x6a 0x04>;
				};

				jr@3000 {
					compatible = "fsl,sec-v4.0-job-ring";
					reg = <0x3000 0x1000>;
					interrupts = <0x00 0x72 0x04>;
				};
			};

			i2c@30a20000 {
				compatible = "fsl,imx8mp-i2c", "fsl,imx21-i2c";
				#address-cells = <0x01>;
				#size-cells = <0x00>;
				reg = <0x30a20000 0x10000>;
				interrupts = <0x00 0x23 0x04>;
				clocks = <0x02 0xcd>;
				status = "okay";
				clock-frequency = <0x61a80>;
				pinctrl-names = "default", "gpio";
				pinctrl-0 = <0x28>;
				pinctrl-1 = <0x29>;
				scl-gpios = <0x2a 0x0e 0x00>;
				sda-gpios = <0x2a 0x0f 0x00>;

				pmic@25 {
					compatible = "nxp,pca9450c";
					reg = <0x25>;
					pinctrl-names = "default";
					pinctrl-0 = <0x2b>;
					interrupt-parent = <0x2c>;
					interrupts = <0x03 0x08>;
					nxp,i2c-lt-enable;

					regulators {

						BUCK1 {
							regulator-name = "BUCK1";
							regulator-min-microvolt = <0x927c0>;
							regulator-max-microvolt = <0x2160ec>;
							regulator-boot-on;
							regulator-always-on;
							regulator-ramp-delay = <0xc35>;
						};

						BUCK2 {
							regulator-name = "BUCK2";
							regulator-min-microvolt = <0x927c0>;
							regulator-max-microvolt = <0x2160ec>;
							regulator-boot-on;
							regulator-always-on;
							regulator-ramp-delay = <0xc35>;
							nxp,dvs-run-voltage = <0xe7ef0>;
							nxp,dvs-standby-voltage = <0xcf850>;
							phandle = <0x07>;
						};

						BUCK4 {
							regulator-name = "BUCK4";
							regulator-min-microvolt = <0x927c0>;
							regulator-max-microvolt = <0x33e140>;
							regulator-boot-on;
							regulator-always-on;
						};

						BUCK5 {
							regulator-name = "BUCK5";
							regulator-min-microvolt = <0x927c0>;
							regulator-max-microvolt = <0x33e140>;
							regulator-boot-on;
							regulator-always-on;
						};

						BUCK6 {
							regulator-name = "BUCK6";
							regulator-min-microvolt = <0x927c0>;
							regulator-max-microvolt = <0x33e140>;
							regulator-boot-on;
							regulator-always-on;
						};

						LDO1 {
							regulator-name = "LDO1";
							regulator-min-microvolt = <0x186a00>;
							regulator-max-microvolt = <0x325aa0>;
							regulator-boot-on;
							regulator-always-on;
						};

						LDO2 {
							regulator-name = "LDO2";
							regulator-min-microvolt = "", "\f5";
							regulator-max-microvolt = <0x118c30>;
							regulator-boot-on;
							regulator-always-on;
						};

						LDO3 {
							regulator-name = "LDO3";
							regulator-min-microvolt = "", "\f5";
							regulator-max-microvolt = <0x325aa0>;
							regulator-boot-on;
							regulator-always-on;
						};

						LDO4 {
							regulator-name = "LDO4";
							regulator-min-microvolt = "", "\f5";
							regulator-max-microvolt = <0x325aa0>;
							regulator-boot-on;
							regulator-always-on;
						};

						LDO5 {
							regulator-name = "LDO5";
							regulator-min-microvolt = <0x1b7740>;
							regulator-max-microvolt = <0x325aa0>;
							regulator-boot-on;
							regulator-always-on;
						};
					};
				};

				s35390a@30 {
					compatible = "sii,s35390a";
					reg = <0x30>;
					status = "okay";
				};

				st33htpi@2e {
					compatible = "st,st33htpm-i2c";
					reg = <0x2e>;
					pinctrl-names = "default";
					pinctrl-0 = <0x2d>;
					interrupt-parent = <0x2e>;
					interrupts = <0x17 0x04>;
				};

				tca9538@71 {
					compatible = "nxp,pca9538";
					reg = <0x71>;
					gpio-controller;
					#gpio-cells = <0x02>;
					phandle = <0xa8>;
				};

				tca9538@70 {
					compatible = "nxp,pca9538";
					reg = <0x70>;
					gpio-controller;
					#gpio-cells = <0x02>;
				};

				sgtl5000@a {
					compatible = "fsl,sgtl5000";
					reg = <0x0a>;
					clocks = <0x2f 0x09>;
					clock-names = "mclk";
					pinctrl-names = "default";
					phandle = <0xab>;
				};

				msp430g2202@29 {
					compatible = "fsl,adv-wdt-i2c";
					reg = <0x29>;
					pinctrl-names = "default";
					pinctrl-0 = <0x30 0x31>;
					wdt-en = <0x2e 0x13 0x00>;
					wdt-ping = <0x32 0x14 0x00>;
					status = "okay";
				};
			};

			i2c@30a30000 {
				compatible = "fsl,imx8mp-i2c", "fsl,imx21-i2c";
				#address-cells = <0x01>;
				#size-cells = <0x00>;
				reg = <0x30a30000 0x10000>;
				interrupts = <0x00 0x24 0x04>;
				clocks = <0x02 0xce>;
				status = "okay";
				clock-frequency = <0x61a80>;
				pinctrl-names = "default", "gpio";
				pinctrl-0 = <0x33>;
				pinctrl-1 = <0x34>;
				scl-gpios = <0x2a 0x10 0x00>;
				sda-gpios = <0x2a 0x11 0x00>;

				ov5640_mipi@3c {
					compatible = "ovti,ov5640";
					reg = <0x3c>;
					pinctrl-names = "default";
					pinctrl-0 = <0x35 0x36 0x37>;
					clocks = <0x02 0xa4>;
					clock-names = "xclk";
					assigned-clocks = <0x02 0xa4>;
					assigned-clock-parents = <0x02 0x02>;
					assigned-clock-rates = <0x16e3600>;
					csi_id = <0x00>;
					powerdown-gpios = <0x38 0x06 0x00>;
					reset-gpios = <0x38 0x07 0x01>;
					mclk = <0x16e3600>;
					mclk_source = <0x00>;
					mipi_csi;
					status = "okay";

					port {

						endpoint {
							remote-endpoint = <0x39>;
							data-lanes = <0x01 0x02>;
							clock-lanes = <0x00>;
							phandle = <0x72>;
						};
					};
				};
			};

			i2c@30a40000 {
				compatible = "fsl,imx8mp-i2c", "fsl,imx21-i2c";
				#address-cells = <0x01>;
				#size-cells = <0x00>;
				reg = <0x30a40000 0x10000>;
				interrupts = <0x00 0x25 0x04>;
				clocks = <0x02 0xcf>;
				status = "okay";
				clock-frequency = <0x61a80>;
				pinctrl-names = "default", "gpio";
				pinctrl-0 = <0x3a>;
				pinctrl-1 = <0x3b>;
				scl-gpios = <0x2a 0x12 0x00>;
				sda-gpios = <0x2a 0x13 0x00>;

				ov5640_mipi@3c {
					compatible = "ovti,ov5640";
					reg = <0x3c>;
					pinctrl-names = "default";
					pinctrl-0 = <0x3c 0x3d 0x3e>;
					clocks = <0x02 0xa5>;
					clock-names = "xclk";
					assigned-clocks = <0x02 0xa5>;
					assigned-clock-parents = <0x02 0x02>;
					assigned-clock-rates = <0x16e3600>;
					csi_id = <0x01>;
					powerdown-gpios = <0x38 0x08 0x00>;
					reset-gpios = <0x38 0x09 0x01>;
					mclk = <0x16e3600>;
					mclk_source = <0x00>;
					mipi_csi;
					status = "okay";

					port {

						endpoint {
							remote-endpoint = <0x3f>;
							data-lanes = <0x01 0x02>;
							clock-lanes = <0x00>;
							phandle = <0x74>;
						};
					};
				};
			};

			i2c@30a50000 {
				compatible = "fsl,imx8mp-i2c", "fsl,imx21-i2c";
				#address-cells = <0x01>;
				#size-cells = <0x00>;
				reg = <0x30a50000 0x10000>;
				interrupts = <0x00 0x26 0x04>;
				clocks = <0x02 0xd0>;
				status = "okay";
				clock-frequency = <0x186a0>;
				pinctrl-names = "default", "gpio";
				pinctrl-0 = <0x40>;
				pinctrl-1 = <0x41>;
				scl-gpios = <0x2a 0x0c 0x00>;
				sda-gpios = <0x2a 0x0d 0x00>;

				24c02@50 {
					compatible = "atmel,24c02";
					reg = <0x50>;
				};
			};

			serial@30a60000 {
				compatible = "fsl,imx8mp-uart", "fsl,imx6q-uart";
				reg = <0x30a60000 0x10000>;
				interrupts = <0x00 0x1d 0x04>;
				clocks = <0x02 0xfe 0x02 0xfe>;
				clock-names = "ipg", "per";
				dmas = <0x21 0x1c 0x04 0x00 0x21 0x1d 0x04 0x00>;
				dma-names = "rx", "tx";
				status = "okay";
				pinctrl-names = "default";
				pinctrl-0 = <0x42>;
			};

			mailbox@30aa0000 {
				compatible = "fsl,imx8mp-mu", "fsl,imx6sx-mu";
				reg = <0x30aa0000 0x10000>;
				interrupts = <0x00 0x58 0x04>;
				clocks = <0x02 0xd5>;
				#mbox-cells = <0x02>;
			};

			mailbox@30e60000 {
				compatible = "fsl,imx8-mu-dsp", "fsl,imx6sx-mu";
				reg = <0x30e60000 0x10000>;
				interrupts = <0x00 0x88 0x04>;
				fsl,dsp_ap_mu_id = <0x02>;
				#mbox-cells = <0x02>;
				clocks = <0x2f 0x24>;
				status = "okay";
				phandle = <0x8e>;
			};

			i2c@30ad0000 {
				compatible = "fsl,imx8mp-i2c", "fsl,imx21-i2c";
				#address-cells = <0x01>;
				#size-cells = <0x00>;
				reg = <0x30ad0000 0x10000>;
				interrupts = <0x00 0x4c 0x04>;
				clocks = <0x02 0xe7>;
				status = "disabled";
			};

			i2c@30ae0000 {
				compatible = "fsl,imx8mp-i2c", "fsl,imx21-i2c";
				#address-cells = <0x01>;
				#size-cells = <0x00>;
				reg = <0x30ae0000 0x10000>;
				interrupts = <0x00 0x4d 0x04>;
				clocks = <0x02 0xe8>;
				status = "disabled";
			};

			mmc@30b40000 {
				compatible = "fsl,imx8mp-usdhc", "fsl,imx8mm-usdhc", "fsl,imx7d-usdhc";
				reg = <0x30b40000 0x10000>;
				interrupts = <0x00 0x16 0x04>;
				clocks = <0x02 0x00 0x02 0x5f 0x02 0x101>;
				clock-names = "ipg", "ahb", "per";
				fsl,tuning-start-tap = <0x14>;
				fsl,tuning-step = <0x02>;
				bus-width = <0x04>;
				status = "okay";
				assigned-clocks = <0x02 0x88>;
				assigned-clock-rates = <0x17d78400>;
				pinctrl-names = "default", "state_100mhz", "state_200mhz";
				pinctrl-0 = <0x43 0x44>;
				pinctrl-1 = <0x45 0x44>;
				pinctrl-2 = <0x46 0x44>;
				vmmc-supply = <0x47>;
			};

			mmc@30b50000 {
				compatible = "fsl,imx8mp-usdhc", "fsl,imx8mm-usdhc", "fsl,imx7d-usdhc";
				reg = <0x30b50000 0x10000>;
				interrupts = <0x00 0x17 0x04>;
				clocks = <0x02 0x00 0x02 0x5f 0x02 0x102>;
				clock-names = "ipg", "ahb", "per";
				fsl,tuning-start-tap = <0x14>;
				fsl,tuning-step = <0x02>;
				bus-width = <0x04>;
				status = "okay";
				assigned-clocks = <0x02 0x89>;
				assigned-clock-rates = <0x17d78400>;
				pinctrl-names = "default", "state_100mhz", "state_200mhz";
				pinctrl-0 = <0x48 0x49>;
				pinctrl-1 = <0x4a 0x49>;
				pinctrl-2 = <0x4b 0x49>;
				cd-gpios = <0x38 0x0c 0x01>;
				vmmc-supply = <0x4c>;
			};

			mmc@30b60000 {
				compatible = "fsl,imx8mp-usdhc", "fsl,imx8mm-usdhc", "fsl,imx7d-usdhc";
				reg = <0x30b60000 0x10000>;
				interrupts = <0x00 0x18 0x04>;
				clocks = <0x02 0x00 0x02 0x5f 0x02 0x115>;
				clock-names = "ipg", "ahb", "per";
				fsl,tuning-start-tap = <0x14>;
				fsl,tuning-step = <0x02>;
				bus-width = <0x08>;
				status = "okay";
				assigned-clocks = <0x02 0xa9>;
				assigned-clock-rates = <0x17d78400>;
				pinctrl-names = "default", "state_100mhz", "state_200mhz";
				pinctrl-0 = <0x4d>;
				pinctrl-1 = <0x4e>;
				pinctrl-2 = <0x4f>;
				cqe-disabled;
				non-removable;
			};

			spi@30bb0000 {
				compatible = "nxp,imx8mp-fspi";
				reg = <0x30bb0000 0x10000 0x8000000 0x10000000>;
				reg-names = "fspi_base", "fspi_mmap";
				interrupts = <0x00 0x6b 0x04>;
				clocks = <0x02 0xe2 0x02 0xe2>;
				clock-names = "fspi_en", "fspi";
				assigned-clock-rates = <0x4c4b400>;
				assigned-clocks = <0x02 0x87>;
				#address-cells = <0x01>;
				#size-cells = <0x00>;
				status = "okay";
				pinctrl-names = "default";
				pinctrl-0 = <0x50>;

				w25q64jwssiq@0 {
					reg = <0x00>;
					#address-cells = <0x01>;
					#size-cells = <0x01>;
					compatible = "jedec,spi-nor", "winbond,w25q64";
					spi-max-frequency = <0x1ba8140>;
					spi-tx-bus-width = <0x04>;
					spi-rx-bus-width = <0x04>;
				};
			};

			dma-controller@30bd0000 {
				compatible = "fsl,imx8mq-sdma";
				reg = <0x30bd0000 0x10000>;
				interrupts = <0x00 0x02 0x04>;
				clocks = <0x02 0xec 0x02 0x6b>;
				clock-names = "ipg", "ahb";
				#dma-cells = <0x03>;
				fsl,sdma-ram-script-name = "imx/sdma/sdma-imx7d.bin";
				phandle = <0x21>;
			};

			ethernet@30be0000 {
				compatible = "fsl,imx8mp-fec", "fsl,imx8mq-fec", "fsl,imx6sx-fec";
				reg = <0x30be0000 0x10000>;
				interrupts = <0x00 0x76 0x04 0x00 0x77 0x04 0x00 0x78 0x04 0x00 0x79 0x04>;
				clocks = <0x02 0xc0 0x02 0xf2 0x02 0x84 0x02 0x83 0x02 0x85>;
				clock-names = "ipg", "ahb", "ptp", "enet_clk_ref", "enet_out";
				assigned-clocks = <0x02 0x5e 0x02 0x84 0x02 0x83 0x02 0x85>;
				assigned-clock-parents = <0x02 0x36 0x02 0x3a 0x02 0x3b 0x02 0x39>;
				assigned-clock-rates = <0x00 0x5f5e100 0x7735940 0x00>;
				fsl,num-tx-queues = <0x03>;
				fsl,num-rx-queues = <0x03>;
				nvmem-cells = <0x51>;
				nvmem-cell-names = "mac-address";
				fsl,stop-mode = <0x25 0x10 0x03>;
				status = "okay";
				pinctrl-names = "default";
				pinctrl-0 = <0x52>;
				phy-mode = "rgmii-id";
				phy-handle = <0x53>;
				fsl,magic-packet;

				mdio {
					#address-cells = <0x01>;
					#size-cells = <0x00>;

					ethernet-phy@1 {
						compatible = "ethernet-phy-ieee802.3-c22";
						reg = <0x01>;
						eee-broken-1000t;
						reset-gpios = <0x32 0x02 0x01>;
						reset-assert-us = <0x2710>;
						reset-deassert-us = <0x13880>;
						realtek,aldps-enable;
						realtek,clkout-disable;
						phandle = <0x53>;
					};
				};
			};

			ethernet@30bf0000 {
				compatible = "nxp,imx8mp-dwmac-eqos", "snps,dwmac-5.10a";
				reg = <0x30bf0000 0x10000>;
				interrupts = <0x00 0x87 0x04 0x00 0x86 0x04>;
				interrupt-names = "macirq", "eth_wake_irq";
				clocks = <0x02 0xed 0x02 0xe1 0x02 0x82 0x02 0x81>;
				clock-names = "stmmaceth", "pclk", "ptp_ref", "tx";
				assigned-clocks = <0x02 0x5e 0x02 0x82 0x02 0x81>;
				assigned-clock-parents = <0x02 0x36 0x02 0x3a 0x02 0x3b>;
				assigned-clock-rates = <0x00 0x5f5e100 0x7735940>;
				nvmem-cells = <0x54>;
				nvmem-cell-names = "mac-address";
				intf_mode = <0x25 0x04>;
				status = "okay";
				pinctrl-names = "default";
				pinctrl-0 = <0x55>;
				phy-mode = "rgmii-id";
				phy-handle = <0x56>;
				snps,force_thresh_dma_mode;
				snps,mtl-tx-config = <0x57>;
				snps,mtl-rx-config = <0x58>;

				mdio {
					compatible = "snps,dwmac-mdio";
					#address-cells = <0x01>;
					#size-cells = <0x00>;

					ethernet-phy@1 {
						compatible = "ethernet-phy-ieee802.3-c22";
						reg = <0x01>;
						eee-broken-1000t;
						reset-gpios = <0x32 0x16 0x01>;
						reset-assert-us = <0x2710>;
						reset-deassert-us = <0x13880>;
						realtek,clkout-disable;
						phandle = <0x56>;
					};
				};

				tx-queues-config {
					snps,tx-queues-to-use = <0x05>;
					snps,tx-sched-sp;
					phandle = <0x57>;

					queue0 {
						snps,dcb-algorithm;
						snps,priority = <0x01>;
					};

					queue1 {
						snps,dcb-algorithm;
						snps,priority = <0x02>;
					};

					queue2 {
						snps,dcb-algorithm;
						snps,priority = <0x04>;
					};

					queue3 {
						snps,dcb-algorithm;
						snps,priority = <0x08>;
					};

					queue4 {
						snps,dcb-algorithm;
						snps,priority = <0xf0>;
					};
				};

				rx-queues-config {
					snps,rx-queues-to-use = <0x05>;
					snps,rx-sched-sp;
					phandle = <0x58>;

					queue0 {
						snps,dcb-algorithm;
						snps,priority = <0x01>;
						snps,map-to-dma-channel = <0x00>;
					};

					queue1 {
						snps,dcb-algorithm;
						snps,priority = <0x02>;
						snps,map-to-dma-channel = <0x01>;
					};

					queue2 {
						snps,dcb-algorithm;
						snps,priority = <0x04>;
						snps,map-to-dma-channel = <0x02>;
					};

					queue3 {
						snps,dcb-algorithm;
						snps,priority = <0x08>;
						snps,map-to-dma-channel = <0x03>;
					};

					queue4 {
						snps,dcb-algorithm;
						snps,priority = <0xf0>;
						snps,map-to-dma-channel = <0x04>;
					};
				};
			};
		};

		interconnect@32700000 {
			compatible = "fsl,imx8mp-noc", "fsl,imx8m-noc", "syscon";
			reg = <0x32700000 0x100000>;
		};

		bus@32c00000 {
			compatible = "fsl,aips-bus", "simple-bus";
			reg = <0x32c00000 0x400000>;
			#address-cells = <0x01>;
			#size-cells = <0x01>;
			ranges;

			mipi_dsi@32e60000 {
				#address-cells = <0x01>;
				#size-cells = <0x00>;
				compatible = "fsl,imx8mp-mipi-dsim";
				reg = <0x32e60000 0x10000>;
				clocks = <0x02 0x10d 0x02 0xab 0x02 0x10d>;
				clock-names = "cfg", "pll-ref", "apb-root";
				assigned-clocks = <0x02 0xab>;
				assigned-clock-parents = <0x02 0x02>;
				assigned-clock-rates = <0xb71b00>;
				interrupts = <0x00 0x12 0x04>;
				power-domains = <0x59 0x00>;
				status = "disabled";

				port@0 {

					endpoint {
						remote-endpoint = <0x5a>;
						phandle = <0x5b>;
					};
				};
			};

			lcd-controller@32e80000 {
				#address-cells = <0x01>;
				#size-cells = <0x00>;
				compatible = "fsl,imx8mp-lcdif1";
				reg = <0x32e80000 0x10000>;
				clocks = <0x02 0x111 0x02 0x10e 0x02 0x10d>;
				clock-names = "pix", "disp-axi", "disp-apb";
				assigned-clocks = <0x02 0xac 0x02 0x61 0x02 0x62>;
				assigned-clock-parents = <0x02 0x28 0x02 0x41 0x02 0x38>;
				assigned-clock-rates = <0x00 0x1dcd6500 0xbebc200>;
				interrupts = <0x00 0x05 0x04>;
				blk-ctl = <0x59>;
				power-domains = <0x59 0x02>;
				status = "okay";

				port@0 {
					reg = <0x00>;
					phandle = <0x0a>;

					endpoint {
						remote-endpoint = <0x5b>;
						phandle = <0x5a>;
					};
				};
			};

			lcd-controller@32e90000 {
				#address-cells = <0x01>;
				#size-cells = <0x00>;
				compatible = "fsl,imx8mp-lcdif2";
				reg = <0x32e90000 0x10000>;
				clocks = <0x02 0x112 0x02 0x10e 0x02 0x10d>;
				clock-names = "pix", "disp-axi", "disp-apb";
				assigned-clocks = <0x02 0x139 0x02 0x61 0x02 0x62>;
				assigned-clock-parents = <0x02 0x28 0x02 0x41 0x02 0x38>;
				assigned-clock-rates = <0x00 0x1dcd6500 0xbebc200>;
				interrupts = <0x00 0x06 0x04>;
				power-domains = <0x59 0x05>;
				status = "okay";

				port@0 {
					#address-cells = <0x01>;
					#size-cells = <0x00>;
					reg = <0x00>;
					phandle = <0x09>;

					endpoint@0 {
						reg = <0x00>;
						remote-endpoint = <0x5c>;
						phandle = <0x6c>;
					};

					endpoint@1 {
						reg = <0x01>;
						remote-endpoint = <0x5d>;
						phandle = <0x6f>;
					};
				};
			};

			blk-ctrl@32ec0000 {
				compatible = "fsl,imx8mp-media-blk-ctrl", "syscon";
				reg = <0x32ec0000 0x10000>;
				power-domains = <0x5e 0x5f 0x5f 0x5e 0x5e 0x60 0x5e 0x61 0x61 0x60>;
				power-domain-names = "bus", "mipi-dsi1", "mipi-csi1", "lcdif1", "isi", "mipi-csi2", "lcdif2", "isp", "dwe", "mipi-dsi2";
				clocks = <0x02 0x10d 0x02 0x10e 0x02 0x10f 0x02 0x110 0x02 0x111 0x02 0x112 0x02 0x114 0x02 0x113>;
				clock-names = "apb", "axi", "cam1", "cam2", "disp1", "disp2", "isp", "phy";
				assigned-clocks = <0x02 0x61 0x02 0x62>;
				assigned-clock-parents = <0x02 0x41 0x02 0x38>;
				assigned-clock-rates = <0x1dcd6500 0xbebc200>;
				#power-domain-cells = <0x01>;
				phandle = <0x59>;
			};

			pcie-phy@32f00000 {
				compatible = "fsl,imx8mp-pcie-phy";
				reg = <0x32f00000 0x10000>;
				resets = <0x62 0x18 0x62 0x19>;
				reset-names = "pciephy", "perst";
				power-domains = <0x63 0x04>;
				#phy-cells = <0x00>;
				status = "okay";
				fsl,refclk-pad-mode = <0x01>;
				clocks = <0x64>;
				clock-names = "ref";
				phandle = <0x7f>;
			};

			blk-ctrl@32f10000 {
				compatible = "fsl,imx8mp-hsio-blk-ctrl", "syscon";
				reg = <0x32f10000 0x24>;
				clocks = <0x02 0xff 0x02 0xd9>;
				clock-names = "usb", "pcie";
				power-domains = <0x65 0x65 0x66 0x67 0x65 0x68>;
				power-domain-names = "bus", "usb", "usb-phy1", "usb-phy2", "pcie", "pcie-phy";
				#power-domain-cells = <0x01>;
				phandle = <0x63>;
			};

			blk-ctrl@32fc0000 {
				compatible = "fsl,imx8mp-hdmi-blk-ctrl", "syscon";
				reg = <0x32fc0000 0x23c>;
				clocks = <0x02 0x63 0x02 0x116 0x02 0xa8 0x02 0xa7>;
				clock-names = "apb", "axi", "ref_266m", "ref_24m";
				power-domains = <0x69 0x69 0x69 0x69 0x69 0x69 0x69 0x6a 0x69 0x69>;
				power-domain-names = "bus", "irqsteer", "lcdif", "pai", "pvi", "trng", "hdmi-tx", "hdmi-tx-phy", "hrv", "hdcp";
				#power-domain-cells = <0x01>;
				status = "okay";
				phandle = <0x79>;
			};

			ldb@32ec005c {
				#address-cells = <0x01>;
				#size-cells = <0x00>;
				compatible = "fsl,imx8mp-ldb";
				clocks = <0x02 0x140>;
				clock-names = "ldb";
				assigned-clocks = <0x02 0xae>;
				assigned-clock-parents = <0x02 0x28>;
				gpr = <0x59>;
				power-domains = <0x5e>;
				status = "okay";

				lvds-channel@0 {
					#address-cells = <0x01>;
					#size-cells = <0x00>;
					reg = <0x00>;
					phys = <0x6b>;
					phy-names = "ldb_phy";
					status = "okay";
					fsl,data-mapping = "spwg";
					fsl,data-width = <0x18>;

					port@0 {
						reg = <0x00>;

						endpoint {
							remote-endpoint = <0x6c>;
							phandle = <0x5c>;
						};
					};

					port@1 {
						reg = <0x01>;

						endpoint {
							remote-endpoint = <0x6d>;
							phandle = <0xad>;
						};
					};
				};

				lvds-channel@1 {
					#address-cells = <0x01>;
					#size-cells = <0x00>;
					reg = <0x01>;
					phys = <0x6e>;
					phy-names = "ldb_phy";
					status = "disabled";

					port@0 {
						reg = <0x00>;

						endpoint {
							remote-endpoint = <0x6f>;
							phandle = <0x5d>;
						};
					};
				};
			};

			phy@32ec0128 {
				compatible = "fsl,imx8mp-lvds-phy";
				#address-cells = <0x01>;
				#size-cells = <0x00>;
				gpr = <0x59>;
				clocks = <0x02 0x10d>;
				clock-names = "apb";
				power-domains = <0x5e>;
				status = "okay";

				port@0 {
					reg = <0x00>;
					#phy-cells = <0x00>;
					phandle = <0x6b>;
				};

				port@1 {
					reg = <0x01>;
					#phy-cells = <0x00>;
					phandle = <0x6e>;
				};
			};

			media_gpr@32ec0008 {
				compatible = "fsl,imx8mp-iomuxc-gpr", "syscon";
				reg = <0x32ec0008 0x04>;
			};

			gasket@32ec0060 {
				compatible = "fsl,imx8mp-iomuxc-gpr", "syscon";
				reg = <0x32ec0060 0x28>;
				phandle = <0x71>;
			};

			gasket@32ec0090 {
				compatible = "fsl,imx8mp-iomuxc-gpr", "syscon";
				reg = <0x32ec0090 0x28>;
				phandle = <0x73>;
			};

			isi_chain@32e02000 {
				compatible = "fsl,imx8mp-iomuxc-gpr", "syscon";
				reg = <0x32e02000 0x04>;
				phandle = <0x70>;
			};

			camera {
				compatible = "fsl,mxc-md", "simple-bus";
				#address-cells = <0x01>;
				#size-cells = <0x01>;
				ranges;
				status = "okay";

				isi@32e00000 {
					compatible = "fsl,imx8mp-isi", "fsl,imx8mn-isi";
					reg = <0x32e00000 0x2000>;
					interrupts = <0x00 0x10 0x04>;
					interface = <0x02 0x00 0x02>;
					clocks = <0x02 0x61 0x02 0x62 0x02 0x10e 0x02 0x10d>;
					clock-names = "disp_axi", "disp_apb", "disp_axi_root", "disp_apb_root";
					assigned-clocks = <0x02 0x10e 0x02 0x10d>;
					assigned-clock-rates = <0x1dcd6500 0xbebc200>;
					power-domains = <0x59 0x03>;
					isi_chain = <0x70>;
					status = "okay";

					cap_device {
						compatible = "imx-isi-capture";
						status = "okay";
					};

					m2m_device {
						compatible = "imx-isi-m2m";
						status = "disabled";
					};
				};

				isi@32e02000 {
					compatible = "fsl,imx8mp-isi", "fsl,imx8mn-isi";
					reg = <0x32e02000 0x2000>;
					interrupts = <0x00 0x2a 0x04>;
					interface = <0x03 0x00 0x02>;
					clocks = <0x02 0x61 0x02 0x62 0x02 0x10e 0x02 0x10d>;
					clock-names = "disp_axi", "disp_apb", "disp_axi_root", "disp_apb_root";
					assigned-clocks = <0x02 0x10e 0x02 0x10d>;
					assigned-clock-rates = <0x1dcd6500 0xbebc200>;
					power-domains = <0x59 0x03>;
					status = "okay";

					cap_device {
						compatible = "imx-isi-capture";
						status = "okay";
					};
				};

				dwe@32e30000 {
					compatible = "fsl,imx8mp-dwe";
					clocks = <0x02 0x10e 0x02 0x10e 0x02 0x10d>;
					clock-names = "core", "axi", "ahb";
					reg = <0x32e30000 0x10000>;
					interrupts = <0x00 0x64 0x04>;
					power-domains = <0x59 0x07>;
					status = "disabled";
				};

				isp@32e10000 {
					compatible = "fsl,imx8mp-isp";
					reg = <0x32e10000 0x10000>;
					interrupts = <0x00 0x4a 0x04>;
					clocks = <0x02 0x114 0x02 0x10e 0x02 0x10d 0x02 0x10f>;
					clock-names = "core", "axi", "ahb", "sensor";
					assigned-clocks = <0x02 0x138>;
					assigned-clock-parents = <0x02 0x40>;
					assigned-clock-rates = <0x1dcd6500>;
					power-domains = <0x59 0x01 0x59 0x06>;
					id = <0x00>;
					gpr = <0x59>;
					status = "disabled";
				};

				isp@32e20000 {
					compatible = "fsl,imx8mp-isp";
					reg = <0x32e20000 0x10000>;
					interrupts = <0x00 0x4b 0x04>;
					clocks = <0x02 0x114 0x02 0x10e 0x02 0x10d 0x02 0x10f>;
					clock-names = "core", "axi", "ahb", "sensor";
					assigned-clocks = <0x02 0x138>;
					assigned-clock-parents = <0x02 0x40>;
					assigned-clock-rates = <0x1dcd6500>;
					power-domains = <0x59 0x01 0x59 0x06>;
					id = <0x01>;
					gpr = <0x59>;
					status = "disabled";
				};

				csi@32e40000 {
					compatible = "fsl,imx8mp-mipi-csi", "fsl,imx8mn-mipi-csi";
					reg = <0x32e40000 0x10000>;
					interrupts = <0x00 0x11 0x04>;
					clock-frequency = <0x1dcd6500>;
					clocks = <0x02 0x10f 0x02 0x61 0x02 0x10d>;
					clock-names = "mipi_clk", "disp_axi", "disp_apb";
					assigned-clocks = <0x02 0xaa>;
					assigned-clock-parents = <0x02 0x41>;
					assigned-clock-rates = <0x1dcd6500>;
					bus-width = <0x04>;
					csi-gpr = <0x71>;
					gpr = <0x59>;
					power-domains = <0x59 0x01>;
					status = "okay";
					#address-cells = <0x01>;
					#size-cells = <0x00>;

					port@0 {
						reg = <0x00>;

						endpoint {
							remote-endpoint = <0x72>;
							data-lanes = <0x02>;
							csis-hs-settle = <0x0d>;
							csis-clk-settle = <0x02>;
							csis-wclk;
							phandle = <0x39>;
						};
					};
				};

				csi@32e50000 {
					compatible = "fsl,imx8mp-mipi-csi", "fsl,imx8mn-mipi-csi";
					reg = <0x32e50000 0x10000>;
					interrupts = <0x00 0x50 0x04>;
					clock-frequency = <0xfdad680>;
					clocks = <0x02 0x110 0x02 0x61 0x02 0x10d>;
					clock-names = "mipi_clk", "disp_axi", "disp_apb";
					assigned-clocks = <0x02 0xad>;
					assigned-clock-parents = <0x02 0x36>;
					assigned-clock-rates = <0xfdad680>;
					bus-width = <0x04>;
					csi-gpr = <0x73>;
					gpr = <0x59>;
					power-domains = <0x59 0x04>;
					status = "okay";
					#address-cells = <0x01>;
					#size-cells = <0x00>;

					port@1 {
						reg = <0x01>;

						endpoint {
							remote-endpoint = <0x74>;
							data-lanes = <0x02>;
							csis-hs-settle = <0x0d>;
							csis-clk-settle = <0x02>;
							csis-wclk;
							phandle = <0x3f>;
						};
					};
				};
			};
		};

		bus@30c00000 {
			compatible = "fsl,aips-bus", "simple-bus";
			reg = <0x30c00000 0x400000>;
			#address-cells = <0x01>;
			#size-cells = <0x01>;
			ranges;

			spba-bus@30c00000 {
				compatible = "fsl,spba-bus", "simple-bus";
				reg = <0x30c00000 0x100000>;
				#address-cells = <0x01>;
				#size-cells = <0x01>;
				ranges;

				sai@30c10000 {
					compatible = "fsl,imx8mp-sai", "fsl,imx8mm-sai";
					reg = <0x30c10000 0x10000>;
					interrupts = <0x00 0x5f 0x04>;
					clocks = <0x2f 0x00 0x02 0x00 0x2f 0x01 0x02 0x00 0x02 0x00>;
					clock-names = "bus", "mclk0", "mclk1", "mclk2", "mclk3";
					dmas = <0x75 0x00 0x02 0x00 0x75 0x01 0x02 0x00>;
					dma-names = "rx", "tx";
					fsl,shared-interrupt;
					fsl,dataline = <0x00 0xff 0xff>;
					power-domains = <0x76>;
					status = "disabled";
				};

				sai@30c20000 {
					compatible = "fsl,imx8mp-sai", "fsl,imx8mm-sai";
					reg = <0x30c20000 0x10000>;
					interrupts = <0x00 0x60 0x04>;
					clocks = <0x2f 0x04 0x02 0x00 0x2f 0x05 0x02 0x00 0x02 0x00>;
					clock-names = "bus", "mclk0", "mclk1", "mclk2", "mclk3";
					dmas = <0x75 0x02 0x02 0x00 0x75 0x03 0x02 0x00>;
					dma-names = "rx", "tx";
					fsl,shared-interrupt;
					fsl,dataline = <0x00 0x0f 0x0f>;
					power-domains = <0x76>;
					status = "okay";
					#sound-dai-cells = <0x00>;
					pinctrl-names = "default";
					pinctrl-0 = <0x77>;
					assigned-clocks = <0x02 0x7c>;
					assigned-clock-parents = <0x02 0x26>;
					assigned-clock-rates = <0xbb8000>;
				};

				sai@30c30000 {
					compatible = "fsl,imx8mp-sai", "fsl,imx8mm-sai";
					reg = <0x30c30000 0x10000>;
					interrupts = <0x00 0x32 0x04>;
					clocks = <0x2f 0x08 0x02 0x00 0x2f 0x09 0x02 0x00 0x02 0x00>;
					clock-names = "bus", "mclk0", "mclk1", "mclk2", "mclk3";
					dmas = <0x75 0x04 0x02 0x00 0x75 0x05 0x02 0x00>;
					dma-names = "rx", "tx";
					fsl,shared-interrupt;
					fsl,dataline = <0x00 0x03 0x03>;
					power-domains = <0x76>;
					status = "okay";
					pinctrl-names = "default";
					pinctrl-0 = <0x78>;
					assigned-clocks = <0x02 0x7d>;
					assigned-clock-parents = <0x02 0x26>;
					assigned-clock-rates = <0xbb8000>;
					fsl,sai-mclk-direction-output;
					fsl,sai-mclk-always-on;
					phandle = <0xaa>;
				};

				sai@30c50000 {
					compatible = "fsl,imx8mp-sai", "fsl,imx8mm-sai";
					reg = <0x30c50000 0x10000>;
					interrupts = <0x00 0x5a 0x04>;
					clocks = <0x2f 0x0c 0x02 0x00 0x2f 0x0d 0x02 0x00 0x02 0x00>;
					clock-names = "bus", "mclk0", "mclk1", "mclk2", "mclk3";
					dmas = <0x75 0x08 0x02 0x00 0x75 0x09 0x02 0x00>;
					dma-names = "rx", "tx";
					fsl,shared-interrupt;
					fsl,dataline = <0x00 0x0f 0x0f>;
					power-domains = <0x76>;
					status = "disabled";
				};

				sai@30c60000 {
					compatible = "fsl,imx8mp-sai", "fsl,imx8mm-sai";
					reg = <0x30c60000 0x10000>;
					interrupts = <0x00 0x5a 0x04>;
					clocks = <0x2f 0x10 0x02 0x00 0x2f 0x11 0x02 0x00 0x02 0x00>;
					clock-names = "bus", "mclk0", "mclk1", "mclk2", "mclk3";
					dmas = <0x75 0x0a 0x02 0x00 0x75 0x0b 0x02 0x00>;
					dma-names = "rx", "tx";
					fsl,shared-interrupt;
					power-domains = <0x76>;
					status = "disabled";
				};

				sai@30c80000 {
					compatible = "fsl,imx8mp-sai", "fsl,imx8mm-sai";
					reg = <0x30c80000 0x10000>;
					interrupts = <0x00 0x6f 0x04>;
					clocks = <0x2f 0x14 0x02 0x00 0x2f 0x15 0x02 0x00 0x02 0x00>;
					clock-names = "bus", "mclk0", "mclk1", "mclk2", "mclk3";
					dmas = <0x75 0x0c 0x02 0x00 0x75 0x0d 0x02 0x00>;
					dma-names = "rx", "tx";
					fsl,shared-interrupt;
					power-domains = <0x76>;
					status = "disabled";
				};

				easrc@30c90000 {
					compatible = "fsl,imx8mn-easrc";
					reg = <0x30c90000 0x10000>;
					interrupts = <0x00 0x7a 0x04>;
					clocks = <0x2f 0x18>;
					clock-names = "mem";
					dmas = <0x75 0x10 0x17 0x00 0x75 0x11 0x17 0x00 0x75 0x12 0x17 0x00 0x75 0x13 0x17 0x00 0x75 0x14 0x17 0x00 0x75 0x15 0x17 0x00 0x75 0x16 0x17 0x00 0x75 0x17 0x17 0x00>;
					dma-names = "ctx0_rx", "ctx0_tx", "ctx1_rx", "ctx1_tx", "ctx2_rx", "ctx2_tx", "ctx3_rx", "ctx3_tx";
					firmware-name = "imx/easrc/easrc-imx8mn.bin";
					fsl,asrc-rate = <0x1f40>;
					fsl,asrc-format = <0x02>;
					power-domains = <0x76>;
					status = "disabled";
				};

				micfil@30ca0000 {
					compatible = "fsl,imx8mp-micfil";
					reg = <0x30ca0000 0x10000>;
					interrupts = <0x00 0x6d 0x04 0x00 0x6e 0x04 0x00 0x2c 0x04 0x00 0x2d 0x04>;
					clocks = <0x2f 0x19 0x2f 0x27 0x02 0x26 0x02 0x27 0x02 0x06>;
					clock-names = "ipg_clk", "ipg_clk_app", "pll8k", "pll11k", "clkext3";
					dmas = <0x75 0x18 0x19 0x80000000>;
					dma-names = "rx";
					power-domains = <0x76>;
					status = "disabled";
				};

				aud2htx@30cb0000 {
					compatible = "fsl,imx8mp-aud2htx";
					reg = <0x30cb0000 0x10000>;
					interrupts = <0x00 0x82 0x04>;
					clocks = <0x2f 0x21>;
					clock-names = "bus";
					dmas = <0x75 0x1a 0x02 0x00>;
					dma-names = "tx";
					power-domains = <0x76>;
					status = "okay";
					phandle = <0xa4>;
				};

				xcvr@30cc0000 {
					compatible = "fsl,imx8mp-xcvr";
					reg = <0x30cc0000 0x800 0x30cc0800 0x400 0x30cc0c00 0x80 0x30cc0e00 0x80>;
					reg-names = "ram", "regs", "rxfifo", "txfifo";
					interrupts = <0x00 0x80 0x04 0x00 0x81 0x04 0x00 0x92 0x04>;
					clocks = <0x2f 0x1f 0x2f 0x26 0x2f 0x1c 0x2f 0x23>;
					clock-names = "ipg", "phy", "spba", "pll_ipg";
					dmas = <0x75 0x1e 0x02 0x00 0x75 0x1f 0x02 0x00>;
					dma-names = "rx", "tx";
					resets = <0x2f 0x00>;
					power-domains = <0x76>;
					status = "disabled";
				};
			};

			dma-controller@30e00000 {
				compatible = "fsl,imx8mp-sdma", "fsl,imx7d-sdma";
				reg = <0x30e00000 0x10000>;
				interrupts = <0x00 0x22 0x04>;
				clocks = <0x2f 0x1b 0x2f 0x1b>;
				clock-names = "ipg", "ahb";
				#dma-cells = <0x03>;
				fsl,sdma-ram-script-name = "imx/sdma/sdma-imx7d.bin";
				fsl,ratio-1-1;
				power-domains = <0x76>;
				status = "disabled";
			};

			dma-controller@30e10000 {
				compatible = "fsl,imx8mp-sdma", "fsl,imx7d-sdma";
				reg = <0x30e10000 0x10000>;
				interrupts = <0x00 0x67 0x04>;
				clocks = <0x02 0x141 0x02 0x141>;
				clock-names = "ipg", "ahb";
				#dma-cells = <0x03>;
				fsl,sdma-ram-script-name = "imx/sdma/sdma-imx7d.bin";
				fsl,ratio-1-1;
				power-domains = <0x76>;
				status = "okay";
				phandle = <0x75>;
			};

			audio-blk-ctrl@30e20000 {
				compatible = "fsl,imx8mp-audio-blk-ctrl-legacy", "syscon";
				reg = <0x30e20000 0x50c>;
				power-domains = <0x76>;
				#clock-cells = <0x01>;
				#reset-cells = <0x01>;
				assigned-clocks = <0x2f 0x39>;
				assigned-clock-parents = <0x2f 0x38>;
				phandle = <0x2f>;
			};

			audiomix_dsp {
				compatible = "fsl,audiomix-dsp";
				power-domains = <0x76>;
			};

			irqsteer@32fc2000 {
				compatible = "fsl,imx-irqsteer";
				reg = <0x32fc2000 0x1000>;
				interrupts = <0x00 0x2b 0x04>;
				interrupt-controller;
				#interrupt-cells = <0x01>;
				fsl,channel = <0x01>;
				fsl,num-irqs = <0x40>;
				clocks = <0x02 0x63>;
				clock-names = "ipg";
				assigned-clocks = <0x02 0x63>;
				assigned-clock-parents = <0x02 0x33>;
				assigned-clock-rates = <0x7ed6b40>;
				power-domains = <0x79 0x00>;
				status = "okay";
				phandle = <0x7b>;
			};

			hdmi-pai-pvi@32fc4000 {
				compatible = "fsl,imx8mp-hdmi-pavi";
				reg = <0x32fc4000 0x1000>;
				clocks = <0x02 0x63>;
				power-domains = <0x79 0x03>;
				status = "okay";
			};

			lcd-controller@32fc6000 {
				#address-cells = <0x01>;
				#size-cells = <0x00>;
				compatible = "fsl,imx8mp-lcdif1";
				reg = <0x32fc6000 0x10000>;
				clocks = <0x7a 0x00 0x02 0x64 0x02 0x63>;
				clock-names = "pix", "disp-axi", "disp-apb";
				power-domains = <0x79 0x01>;
				assigned-clocks = <0x02 0x64 0x02 0x63>;
				assigned-clock-parents = <0x02 0x40 0x02 0x33>;
				assigned-clock-rates = <0x1dcd6500 0x7ed6b40>;
				interrupts = <0x08 0x04>;
				interrupt-parent = <0x7b>;
				status = "okay";
				thres-low = <0x01 0x02>;
				thres-high = <0x03 0x04>;

				port@0 {
					reg = <0x00>;
					phandle = <0x08>;

					endpoint {
						remote-endpoint = <0x7c>;
						phandle = <0x7d>;
					};
				};
			};

			hdmi@32fd8000 {
				compatible = "fsl,imx8mp-hdmi";
				reg = <0x32fd8000 0x7eff>;
				interrupts = <0x00 0x04>;
				interrupt-parent = <0x7b>;
				power-domains = <0x79 0x05>;
				clocks = <0x02 0x63 0x02 0xa7 0x7a 0x00>;
				clock-names = "iahb", "isfr", "pix";
				assigned-clocks = <0x02 0x63 0x02 0x64 0x02 0xa7>;
				assigned-clock-parents = <0x02 0x33 0x02 0x40 0x02 0x02>;
				assigned-clock-rates = <0x7ed6b40 0x1dcd6500 0x16e3600>;
				status = "okay";

				port@0 {

					endpoint {
						remote-endpoint = <0x7d>;
						phandle = <0x7c>;
					};
				};
			};

			hdmiphy@32fdff00 {
				compatible = "fsl,samsung-hdmi-phy";
				reg = <0x32fdff00 0x100>;
				clocks = <0x02 0x63 0x02 0xa7>;
				clock-names = "apb", "ref";
				assigned-clocks = <0x02 0xa7>;
				assigned-clock-parents = <0x02 0x02>;
				#clock-cells = <0x01>;
				clock-output-names = "hdmi_phy";
				#phy-cells = <0x00>;
				power-domains = <0x79 0x06>;
				status = "okay";
				tx_vl_5c = <0x29>;
				tx_vl_60 = <0x52>;
				phandle = <0x7a>;
			};
		};

		dma-apbh@33000000 {
			compatible = "fsl,imx7d-dma-apbh", "fsl,imx28-dma-apbh";
			reg = <0x33000000 0x2000>;
			interrupts = <0x00 0x0c 0x04 0x00 0x0c 0x04 0x00 0x0c 0x04 0x00 0x0c 0x04>;
			interrupt-names = "gpmi0", "gpmi1", "gpmi2", "gpmi3";
			#dma-cells = <0x01>;
			dma-channels = <0x04>;
			clocks = <0x02 0xe4>;
			phandle = <0x7e>;
		};

		gpmi-nand@33002000 {
			compatible = "fsl,imx7d-gpmi-nand";
			#address-cells = <0x01>;
			#size-cells = <0x01>;
			reg = <0x33002000 0x2000 0x33004000 0x4000>;
			reg-names = "gpmi-nand", "bch";
			interrupts = <0x00 0x0e 0x04>;
			interrupt-names = "bch";
			clocks = <0x02 0xe3 0x02 0xe4>;
			clock-names = "gpmi_io", "gpmi_bch_apb";
			dmas = <0x7e 0x00>;
			dma-names = "rx-tx";
			status = "disabled";
		};

		pcie@33800000 {
			compatible = "fsl,imx8mp-pcie";
			reg = <0x33800000 0x400000 0x1ff00000 0x80000>;
			reg-names = "dbi", "config";
			#address-cells = <0x03>;
			#size-cells = <0x02>;
			device_type = "pci";
			bus-range = <0x00 0xff>;
			ranges = <0x81000000 0x00 0x00 0x1ff80000 0x00 0x10000 0x82000000 0x00 0x18000000 0x18000000 0x00 0x7f00000>;
			num-lanes = <0x01>;
			num-viewport = <0x04>;
			interrupts = <0x00 0x8c 0x04>;
			interrupt-names = "msi";
			#interrupt-cells = <0x01>;
			interrupt-map-mask = <0x00 0x00 0x00 0x07>;
			interrupt-map = <0x00 0x00 0x00 0x01 0x01 0x00 0x7e 0x04 0x00 0x00 0x00 0x02 0x01 0x00 0x7d 0x04 0x00 0x00 0x00 0x03 0x01 0x00 0x7c 0x04 0x00 0x00 0x00 0x04 0x01 0x00 0x7b 0x04>;
			fsl,max-link-speed = <0x03>;
			linux,pci-domain = <0x00>;
			power-domains = <0x63 0x03>;
			resets = <0x62 0x1a 0x62 0x1b>;
			reset-names = "apps", "turnoff";
			phys = <0x7f>;
			phy-names = "pcie-phy";
			status = "okay";
			pinctrl-names = "default";
			pinctrl-0 = <0x80>;
			power-on-gpio = <0x2c 0x09 0x01>;
			power-on-gpio2 = <0x2c 0x05 0x01>;
			reset-gpio = <0x2c 0x0a 0x00>;
			clocks = <0x02 0x10c 0x02 0xd9 0x02 0x137>;
			clock-names = "pcie", "pcie_aux", "pcie_bus";
			assigned-clocks = <0x02 0x78>;
			assigned-clock-rates = <0x989680>;
			assigned-clock-parents = <0x02 0x39>;
		};

		pcie_ep@33800000 {
			compatible = "fsl,imx8mp-pcie-ep";
			reg = <0x33800000 0x400000 0x18000000 0x8000000>;
			reg-names = "regs", "addr_space";
			num-lanes = <0x01>;
			interrupts = <0x00 0x7f 0x04>;
			interrupt-names = "dma";
			fsl,max-link-speed = <0x03>;
			power-domains = <0x63 0x03>;
			resets = <0x62 0x1a 0x62 0x1b>;
			reset-names = "apps", "turnoff";
			phys = <0x7f>;
			phy-names = "pcie-phy";
			num-ib-windows = <0x04>;
			num-ob-windows = <0x04>;
			status = "disabled";
		};

		interrupt-controller@38800000 {
			compatible = "arm,gic-v3";
			reg = <0x38800000 0x10000 0x38880000 0xc0000>;
			#interrupt-cells = <0x03>;
			interrupt-controller;
			interrupts = <0x01 0x09 0x04>;
			interrupt-parent = <0x01>;
			phandle = <0x01>;
		};

		blk-ctl@38330000 {
			compatible = "fsl,imx8mp-vpu-blk-ctrl", "syscon";
			reg = <0x38330000 0x100>;
			#power-domain-cells = <0x01>;
			power-domains = <0x1e 0x81 0x82 0x83>;
			power-domain-names = "bus", "g1", "g2", "h1";
			clocks = <0x02 0x106 0x02 0x10a 0x02 0x109>;
			clock-names = "g1", "g2", "h1";
			phandle = <0x86>;
		};

		memory-controller@3d400000 {
			compatible = "snps,ddrc-3.80a";
			reg = <0x3d400000 0x400000>;
			interrupts = <0x00 0x93 0x04>;
		};

		ddr-pmu@3d800000 {
			compatible = "fsl,imx8mp-ddr-pmu", "fsl,imx8m-ddr-pmu";
			reg = <0x3d800000 0x400000>;
			interrupts = <0x00 0x62 0x04>;
		};

		usb-phy@381f0040 {
			compatible = "fsl,imx8mp-usb-phy";
			reg = <0x381f0040 0x40>;
			clocks = <0x02 0x100>;
			clock-names = "phy";
			assigned-clocks = <0x02 0x93>;
			assigned-clock-parents = <0x02 0x02>;
			power-domains = <0x63 0x01>;
			#phy-cells = <0x00>;
			status = "okay";
			fsl,phy-tx-vref-tune = <0x0e>;
			fsl,phy-tx-preemp-amp-tune = <0x03>;
			fsl,phy-tx-vboost-level = <0x05>;
			fsl,phy-comp-dis-tune = <0x07>;
			fsl,pcs-tx-deemph-3p5db = <0x21>;
			fsl,phy-pcs-tx-swing-full = <0x7f>;
			phandle = <0x84>;
		};

		usb@32f10100 {
			compatible = "fsl,imx8mp-dwc3";
			reg = <0x32f10100 0x08 0x381f0000 0x20>;
			clocks = <0x02 0x10c 0x02 0x14a>;
			clock-names = "hsio", "suspend";
			interrupts = <0x00 0x94 0x04>;
			power-domains = <0x63 0x00>;
			#address-cells = <0x01>;
			#size-cells = <0x01>;
			dma-ranges = <0x40000000 0x40000000 0xc0000000>;
			ranges;
			status = "okay";

			usb@38100000 {
				compatible = "snps,dwc3";
				reg = <0x38100000 0x10000>;
				clocks = <0x02 0xff 0x02 0x92 0x02 0x14a>;
				clock-names = "bus_early", "ref", "suspend";
				interrupts = <0x00 0x28 0x04>;
				phys = <0x84 0x84>;
				phy-names = "usb2-phy", "usb3-phy";
				snps,gfladj-refclk-lpm-sel-quirk;
				snps,parkmode-disable-ss-quirk;
				dr_mode = "host";
				status = "okay";
			};
		};

		usb-phy@382f0040 {
			compatible = "fsl,imx8mp-usb-phy";
			reg = <0x382f0040 0x40>;
			clocks = <0x02 0x100>;
			clock-names = "phy";
			assigned-clocks = <0x02 0x93>;
			assigned-clock-parents = <0x02 0x02>;
			power-domains = <0x63 0x02>;
			#phy-cells = <0x00>;
			status = "okay";
			fsl,phy-tx-preemp-amp-tune = <0x03>;
			fsl,phy-tx-vref-tune = <0x0b>;
			phandle = <0x85>;
		};

		usb@32f10108 {
			compatible = "fsl,imx8mp-dwc3";
			reg = <0x32f10108 0x08 0x382f0000 0x20>;
			clocks = <0x02 0x10c 0x02 0x14a>;
			clock-names = "hsio", "suspend";
			interrupts = <0x00 0x95 0x04>;
			power-domains = <0x63 0x00>;
			#address-cells = <0x01>;
			#size-cells = <0x01>;
			dma-ranges = <0x40000000 0x40000000 0xc0000000>;
			ranges;
			status = "okay";

			usb@38200000 {
				compatible = "snps,dwc3";
				reg = <0x38200000 0x10000>;
				clocks = <0x02 0xff 0x02 0x92 0x02 0x14a>;
				clock-names = "bus_early", "ref", "suspend";
				interrupts = <0x00 0x29 0x04>;
				phys = <0x85 0x85>;
				phy-names = "usb2-phy", "usb3-phy";
				snps,gfladj-refclk-lpm-sel-quirk;
				snps,parkmode-disable-ss-quirk;
				dr_mode = "host";
				status = "okay";
			};
		};
	};

	vpu_g1@38300000 {
		compatible = "nxp,imx8mm-hantro", "nxp,imx8mp-hantro";
		reg = <0x00 0x38300000 0x00 0x100000>;
		reg-names = "regs_hantro";
		interrupts = <0x00 0x07 0x04>;
		interrupt-names = "irq_hantro";
		clocks = <0x02 0x106 0x02 0x11a>;
		clock-names = "clk_hantro", "clk_hantro_bus";
		assigned-clocks = <0x02 0x72 0x02 0x60>;
		assigned-clock-parents = <0x02 0x38 0x02 0x38>;
		assigned-clock-rates = <0x2faf0800 0x2faf0800>;
		power-domains = <0x86 0x00>;
		status = "okay";
	};

	vpu_g2@38310000 {
		compatible = "nxp,imx8mm-hantro", "nxp,imx8mp-hantro";
		reg = <0x00 0x38310000 0x00 0x100000>;
		reg-names = "regs_hantro";
		interrupts = <0x00 0x08 0x04>;
		interrupt-names = "irq_hantro";
		clocks = <0x02 0x10a 0x02 0x11a>;
		clock-names = "clk_hantro", "clk_hantro_bus";
		assigned-clocks = <0x02 0x73 0x02 0x60 0x02 0x17>;
		assigned-clock-parents = <0x02 0x2b 0x02 0x38>;
		assigned-clock-rates = <0x29b92700 0x2faf0800 0x29b92700>;
		power-domains = <0x86 0x01>;
		status = "okay";
	};

	vpu_vc8000e@38320000 {
		compatible = "nxp,imx8mp-hantro-vc8000e";
		reg = <0x00 0x38320000 0x00 0x10000>;
		reg-names = "regs_hantro_vc8000e";
		interrupts = <0x00 0x1e 0x04>;
		interrupt-names = "irq_hantro_vc8000e";
		clocks = <0x02 0x109 0x02 0x11a>;
		clock-names = "clk_hantro_vc8000e", "clk_hantro_vc8000e_bus";
		assigned-clocks = <0x02 0xb5 0x02 0x60>;
		assigned-clock-parents = <0x02 0x41 0x02 0x38>;
		assigned-clock-rates = <0x1dcd6500 0x2faf0800>;
		power-domains = <0x86 0x02>;
		status = "okay";
	};

	vpu_v4l2 {
		compatible = "nxp,imx8m-vsiv4l2";
		status = "okay";
	};

	gpu3d@38000000 {
		compatible = "fsl,imx8-gpu";
		reg = <0x00 0x38000000 0x00 0x8000>;
		interrupts = <0x00 0x03 0x04>;
		clocks = <0x02 0xf8 0x02 0x134 0x02 0x65 0x02 0x66>;
		clock-names = "core", "shader", "axi", "ahb";
		assigned-clocks = <0x02 0x133 0x02 0x134 0x02 0x65 0x02 0x66>;
		assigned-clock-parents = <0x02 0x41 0x02 0x41 0x02 0x38 0x02 0x38>;
		assigned-clock-rates = <0x3b9aca00 0x3b9aca00 0x2faf0800 0x17d78400>;
		power-domains = <0x87>;
		status = "okay";
		phandle = <0x8a>;
	};

	gpu2d@38008000 {
		compatible = "fsl,imx8-gpu";
		reg = <0x00 0x38008000 0x00 0x8000>;
		interrupts = <0x00 0x19 0x04>;
		clocks = <0x02 0xf7 0x02 0x65 0x02 0x66>;
		clock-names = "core", "axi", "ahb";
		assigned-clocks = <0x02 0x135 0x02 0x65 0x02 0x66>;
		assigned-clock-parents = <0x02 0x41 0x02 0x38 0x02 0x38>;
		assigned-clock-rates = <0x3b9aca00 0x2faf0800 0x17d78400>;
		power-domains = <0x88>;
		status = "okay";
		phandle = <0x8c>;
	};

	vipsi@38500000 {
		compatible = "fsl,imx8-gpu", "fsl,imx8-vipsi";
		reg = <0x00 0x38500000 0x00 0x20000>;
		interrupts = <0x00 0x0d 0x04>;
		clocks = <0x02 0x10b 0x02 0x10b 0x02 0x69 0x02 0x6a>;
		clock-names = "core", "shader", "axi", "ahb";
		assigned-clocks = <0x02 0x132 0x02 0x69 0x02 0x6a>;
		assigned-clock-parents = <0x02 0x41 0x02 0x38 0x02 0x38>;
		assigned-clock-rates = <0x3b9aca00 0x2faf0800 0x17d78400>;
		power-domains = <0x89>;
		status = "okay";
		phandle = <0x8b>;
	};

	mix_gpu_ml {
		compatible = "fsl,imx8mp-gpu", "fsl,imx8-gpu-ss";
		cores = <0x8a 0x8b 0x8c>;
		reg = <0x00 0x40000000 0x00 0xc0000000 0x00 0x00 0x00 0x10000000>;
		reg-names = "phys_baseaddr", "contiguous_mem";
		memory-region = <0x8d>;
		status = "okay";
	};

	dsp@3b6e8000 {
		compatible = "fsl,imx8mp-hifi4";
		reg = <0x00 0x3b6e8000 0x00 0x88000>;
		clocks = <0x2f 0x20 0x2f 0x1d 0x2f 0x1e>;
		clock-names = "ocram", "core", "debug";
		firmware-name = "imx/dsp/hifi4.bin";
		power-domains = <0x76>;
		mbox-names = "tx", "rx", "rxdb";
		mboxes = <0x8e 0x00 0x00 0x8e 0x01 0x00 0x8e 0x03 0x00>;
		memory-region = <0x8f 0x90 0x91 0x92>;
		fsl,dsp-ctrl = <0x2f>;
		status = "okay";
	};

	i2c-rpbus-3 {
		compatible = "fsl,i2c-rpbus";
		status = "disabled";
	};

	etm@28440000 {
		compatible = "arm,coresight-etm4x", "arm,primecell";
		reg = <0x00 0x28440000 0x00 0x10000>;
		arm,primecell-periphid = <0xbb95d>;
		cpu = <0x0d>;
		clocks = <0x02 0x5d>;
		clock-names = "apb_pclk";
		status = "disabled";

		out-ports {

			port {

				endpoint {
					remote-endpoint = <0x93>;
					phandle = <0x97>;
				};
			};
		};
	};

	etm@28540000 {
		compatible = "arm,coresight-etm4x", "arm,primecell";
		reg = <0x00 0x28540000 0x00 0x10000>;
		arm,primecell-periphid = <0xbb95d>;
		cpu = <0x0e>;
		clocks = <0x02 0x5d>;
		clock-names = "apb_pclk";
		status = "disabled";

		out-ports {

			port {

				endpoint {
					remote-endpoint = <0x94>;
					phandle = <0x98>;
				};
			};
		};
	};

	etm@28640000 {
		compatible = "arm,coresight-etm4x", "arm,primecell";
		reg = <0x00 0x28640000 0x00 0x10000>;
		arm,primecell-periphid = <0xbb95d>;
		cpu = <0x0f>;
		clocks = <0x02 0x5d>;
		clock-names = "apb_pclk";
		status = "disabled";

		out-ports {

			port {

				endpoint {
					remote-endpoint = <0x95>;
					phandle = <0x99>;
				};
			};
		};
	};

	etm@28740000 {
		compatible = "arm,coresight-etm4x", "arm,primecell";
		reg = <0x00 0x28740000 0x00 0x10000>;
		arm,primecell-periphid = <0xbb95d>;
		cpu = <0x10>;
		clocks = <0x02 0x5d>;
		clock-names = "apb_pclk";
		status = "disabled";

		out-ports {

			port {

				endpoint {
					remote-endpoint = <0x96>;
					phandle = <0x9a>;
				};
			};
		};
	};

	funnel {
		compatible = "arm,coresight-static-funnel";
		status = "disabled";

		in-ports {
			#address-cells = <0x01>;
			#size-cells = <0x00>;

			port@0 {
				reg = <0x00>;

				endpoint {
					remote-endpoint = <0x97>;
					phandle = <0x93>;
				};
			};

			port@1 {
				reg = <0x01>;

				endpoint {
					remote-endpoint = <0x98>;
					phandle = <0x94>;
				};
			};

			port@2 {
				reg = <0x02>;

				endpoint {
					remote-endpoint = <0x99>;
					phandle = <0x95>;
				};
			};

			port@3 {
				reg = <0x03>;

				endpoint {
					remote-endpoint = <0x9a>;
					phandle = <0x96>;
				};
			};
		};

		out-ports {

			port {

				endpoint {
					remote-endpoint = <0x9b>;
					phandle = <0x9c>;
				};
			};
		};
	};

	funnel@28c03000 {
		compatible = "arm,coresight-dynamic-funnel", "arm,primecell";
		reg = <0x00 0x28c03000 0x00 0x1000>;
		clocks = <0x02 0x5d>;
		clock-names = "apb_pclk";
		status = "disabled";

		in-ports {
			#address-cells = <0x01>;
			#size-cells = <0x00>;

			port@0 {
				reg = <0x00>;

				endpoint {
					remote-endpoint = <0x9c>;
					phandle = <0x9b>;
				};
			};

			port@1 {
				reg = <0x01>;

				endpoint {
				};
			};

			port@2 {
				reg = <0x02>;

				endpoint {
				};
			};
		};

		out-ports {

			port {

				endpoint {
					remote-endpoint = <0x9d>;
					phandle = <0x9e>;
				};
			};
		};
	};

	etf@28c04000 {
		compatible = "arm,coresight-tmc", "arm,primecell";
		reg = <0x00 0x28c04000 0x00 0x1000>;
		clocks = <0x02 0x5d>;
		clock-names = "apb_pclk";
		status = "disabled";

		in-ports {

			port {

				endpoint {
					remote-endpoint = <0x9e>;
					phandle = <0x9d>;
				};
			};
		};

		out-ports {

			port {

				endpoint {
					remote-endpoint = <0x9f>;
					phandle = <0xa0>;
				};
			};
		};
	};

	etr@28c06000 {
		compatible = "arm,coresight-tmc", "arm,primecell";
		reg = <0x00 0x28c06000 0x00 0x1000>;
		clocks = <0x02 0x5d>;
		clock-names = "apb_pclk";
		status = "disabled";

		in-ports {

			port {

				endpoint {
					remote-endpoint = <0xa0>;
					phandle = <0x9f>;
				};
			};
		};
	};

	chosen {
		stdout-path = "/soc@0/bus@30800000/serial@30880000";
	};

	gpio-leds {
		compatible = "gpio-leds";
		pinctrl-names = "default";
		pinctrl-0 = <0xa1>;

		user {
			label = "user";
			gpios = <0x32 0x1b 0x01>;
			default-state = "off";
		};
	};

	pcie0-refclk {
		compatible = "fixed-clock";
		#clock-cells = <0x00>;
		clock-frequency = <0x5f5e100>;
		phandle = <0x64>;
	};

	regulator-usdhc1 {
		compatible = "regulator-fixed";
		pinctrl-names = "default";
		pinctrl-0 = <0xa2>;
		regulator-name = "WLAN_EN";
		regulator-min-microvolt = <0x325aa0>;
		regulator-max-microvolt = <0x325aa0>;
		gpio = <0x38 0x0a 0x00>;
		enable-active-high;
		phandle = <0x47>;
	};

	regulator-usdhc2 {
		compatible = "regulator-fixed";
		pinctrl-names = "default";
		pinctrl-0 = <0xa3>;
		regulator-name = "VSD_3V3";
		regulator-min-microvolt = <0x325aa0>;
		regulator-max-microvolt = <0x325aa0>;
		gpio = <0x38 0x13 0x00>;
		enable-active-high;
		phandle = <0x4c>;
	};

	sound-hdmi {
		compatible = "fsl,imx-audio-hdmi";
		model = "audio-hdmi";
		audio-cpu = <0xa4>;
		hdmi-out;
		constraint-rate = <0xac44 0x15888 0x2b110 0x7d00 0xbb80 0x17700 0x2ee00>;
		status = "okay";
	};

	lvds_backlight@0 {
		compatible = "pwm-backlight";
		pwms = <0xa5 0x00 0x4c4b40 0x00>;
		status = "okay";
		brightness-levels = <0x00 0x01 0x02 0x03 0x04 0x05 0x06 0x07 0x08 0x09 0x0a 0x0b 0x0c 0x0d 0x0e 0x0f 0x10 0x11 0x12 0x13 0x14 0x15 0x16 0x17 0x18 0x19 0x1a 0x1b 0x1c 0x1d 0x1e 0x1f 0x20 0x21 0x22 0x23 0x24 0x25 0x26 0x27 0x28 0x29 0x2a 0x2b 0x2c 0x2d 0x2e 0x2f 0x30 0x31 0x32 0x33 0x34 0x35 0x36 0x37 0x38 0x39 0x3a 0x3b 0x3c 0x3d 0x3e 0x3f 0x40 0x41 0x42 0x43 0x44 0x45 0x46 0x47 0x48 0x49 0x4a 0x4b 0x4c 0x4d 0x4e 0x4f 0x50 0x51 0x52 0x53 0x54 0x55 0x56 0x57 0x58 0x59 0x5a 0x5b 0x5c 0x5d 0x5e 0x5f 0x60 0x61 0x62 0x63 0x64>;
		default-brightness-level = <0x50>;
		pinctrl-names = "default";
		pinctrl-0 = <0xa6 0xa7>;
		lvds-vcc-enable = <0x2c 0x0d 0x00>;
		lvds-bkl-enable = <0xa8 0x06 0x01>;
		bklt-vcc-enable = <0x2c 0x00 0x01>;
		phandle = <0xac>;
	};

	lvds_backlight@1 {
		compatible = "pwm-backlight";
		pwms = <0xa9 0x00 0x4c4b40 0x00>;
		status = "disabled";
		brightness-levels = <0x00 0x01 0x02 0x03 0x04 0x05 0x06 0x07 0x08 0x09 0x0a 0x0b 0x0c 0x0d 0x0e 0x0f 0x10 0x11 0x12 0x13 0x14 0x15 0x16 0x17 0x18 0x19 0x1a 0x1b 0x1c 0x1d 0x1e 0x1f 0x20 0x21 0x22 0x23 0x24 0x25 0x26 0x27 0x28 0x29 0x2a 0x2b 0x2c 0x2d 0x2e 0x2f 0x30 0x31 0x32 0x33 0x34 0x35 0x36 0x37 0x38 0x39 0x3a 0x3b 0x3c 0x3d 0x3e 0x3f 0x40 0x41 0x42 0x43 0x44 0x45 0x46 0x47 0x48 0x49 0x4a 0x4b 0x4c 0x4d 0x4e 0x4f 0x50 0x51 0x52 0x53 0x54 0x55 0x56 0x57 0x58 0x59 0x5a 0x5b 0x5c 0x5d 0x5e 0x5f 0x60 0x61 0x62 0x63 0x64>;
		default-brightness-level = <0x50>;
	};

	sound {
		compatible = "fsl,sgtl5000", "fsl,imx-audio-sgtl5000";
		model = "sgtl5000";
		codec-master;
		ssi-controller = <0xaa>;
		audio-codec = <0xab>;
		audio-routing = "MIC_IN", "Mic Jack", "Mic Jack", "Mic Bias", "Line Out Jack", "LINE_OUT";
		no-audmux;
	};

	rtl8367 {
		compatible = "realtek,rtl8367b";
		pinctrl-names = "default";
		gpio-sda = <0x2a 0x0a 0x00>;
		gpio-sck = <0x2a 0x0b 0x00>;
		realtek,extif0 = <0x01 0x00 0x01 0x01 0x01 0x01 0x01 0x01 0x02>;
	};

	lvds_panel {
		compatible = "auo,b101aw03", "panel-lvds";
		backlight = <0xac>;
		data-mapping = "spwg";
		width-mm = <0xdf>;
		height-mm = <0x7d>;

		panel-timing {
			clock-frequency = <0x186a000>;
			hactive = <0x400>;
			vactive = <0x258>;
			hfront-porch = <0x9c>;
			hsync-len = <0x08>;
			hback-porch = <0x9c>;
			vfront-porch = <0x10>;
			vsync-len = <0x06>;
			vback-porch = <0x10>;
			hsync-active = <0x00>;
			vsync-active = <0x00>;
			de-active = <0x01>;
			pixelclk-active = <0x00>;
		};

		port {

			endpoint {
				remote-endpoint = <0xad>;
				phandle = <0x6d>;
			};
		};
	};
};
